VERSION "9"

NS_ :

BS_:

BU_: E115DCU

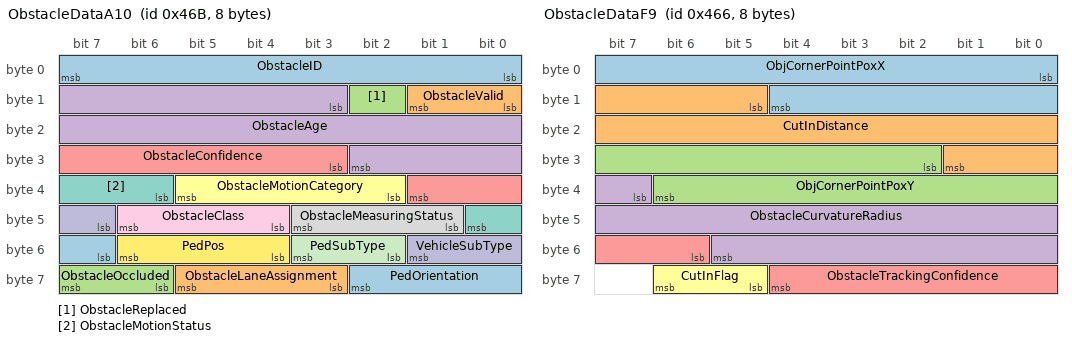
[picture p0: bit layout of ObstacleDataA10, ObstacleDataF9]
BO_ 1131 ObstacleDataA10: 8 E115DCU
 SG_ ObstacleID : 0|8@1+ (1,0) [0|255] "Counter"  E115DCU
 SG_ ObstacleValid : 8|2@1+ (1,0) [0|2] "Enum"  E115DCU
 SG_ ObstacleReplaced : 10|1@1+ (1,0) [0|1] "bool"  E115DCU
 SG_ ObstacleAge : 11|16@1+ (1,0) [0|65535] "Counter"  E115DCU
 SG_ ObstacleConfidence : 27|7@1+ (1,0) [0|100] "prob"  E115DCU
 SG_ ObstacleMotionCategory : 34|4@1+ (1,0) [0|13] "Enum"  E115DCU
 SG_ ObstacleMotionStatus : 38|3@1+ (1,0) [0|7] "Enum"  E115DCU
 SG_ ObstacleMeasuringStatus : 41|3@1+ (1,0) [0|7] "Enum"  E115DCU
 SG_ ObstacleClass : 44|3@1+ (1,0) [0|7] "Enum"  E115DCU
 SG_ VehicleSubType : 47|3@1+ (1,0) [0|7] "Enum"  E115DCU
 SG_ PedSubType : 50|2@1+ (1,0) [0|3] "Enum"  E115DCU
 SG_ PedPos : 52|3@1+ (1,0) [0|7] "Enum"  E115DCU
 SG_ PedOrientation : 55|4@1+ (1,0) [0|9] "Enum"  E115DCU
 SG_ ObstacleLaneAssignment : 59|3@1+ (1,0) [0|5] "Enum"  E115DCU
 SG_ ObstacleOccluded : 62|2@1+ (1,0) [0|3] "Enum"  E115DCU

BO_ 1126 ObstacleDataF9: 8 Vector__XXX
 SG_ ObjCornerPointPoxX : 0|13@1+ (0.0625,-250) [-250|250] "m" Vector__XXX
 SG_ CutInDistance : 13|13@1+ (0.01,-40.96) [-40.96|40.95] "m" Vector__XXX
 SG_ ObjCornerPointPoxY : 26|13@1+ (0.0625,-250) [-250|250] "m" Vector__XXX
 SG_ ObstacleCurvatureRadius : 39|15@1+ (1,-9999) [-9999|9999] "m" Vector__XXX
 SG_ ObstacleTrackingConfidence : 54|7@1+ (1,0) [0|100] "prob" Vector__XXX
 SG_ CutInFlag : 61|2@1+ (1,0) [0|2] "Enum" Vector__XXX

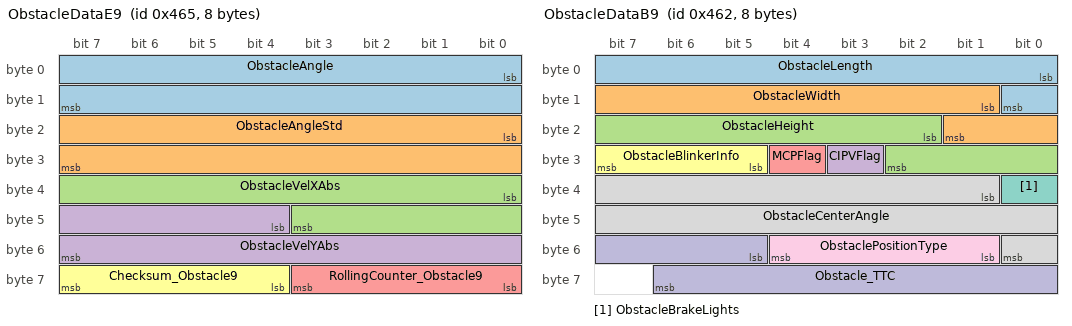
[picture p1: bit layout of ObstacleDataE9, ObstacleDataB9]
BO_ 1125 ObstacleDataE9: 8 E115DCU
 SG_ ObstacleAngle : 0|16@1+ (0.01,-327.68) [-327.68|327.67] "degree"  E115DCU
 SG_ ObstacleAngleStd : 16|16@1+ (0.01,0) [0|327.67] "degree"  E115DCU
 SG_ ObstacleVelXAbs : 32|12@1+ (0.05,-102.4) [-102.4|102.35] "m/sec"  E115DCU
 SG_ ObstacleVelYAbs : 44|12@1+ (0.05,-50) [-50|50] "m/sec"  E115DCU
 SG_ RollingCounter_Obstacle9 : 56|4@1+ (1,0) [0|15] "Counter"  E115DCU
 SG_ Checksum_Obstacle9 : 60|4@1+ (1,0) [0|15] "Counter"  E115DCU

BO_ 1124 ObstacleDataD9: 8 E115DCU
 SG_ ObstaclePosXSTD : 0|13@1+ (0.0625,0) [0|250] "m"  E115DCU
 SG_ ObstaclePosYSTD : 13|13@1+ (0.0625,0) [0|250] "m"  E115DCU
 SG_ ObstacleVelXSTD : 26|12@1+ (0.05,0) [0|102.35] "m/sec"  E115DCU
 SG_ ObstacleVelYSTD : 38|12@1+ (0.05,0) [0|50] "m/sec"  E115DCU
 SG_ ObstacleAccY : 50|10@1+ (0.03,-14.97) [-14.97|14.97] "m/s^2"  E115DCU

BO_ 1123 ObstacleDataC9: 8 E115DCU
 SG_ ObstaclePosX : 0|13@1+ (0.0625,-250) [-250|250] "m"  E115DCU
 SG_ ObstaclePosY : 13|13@1+ (0.0625,-250) [-250|250] "m"  E115DCU
 SG_ ObstacleVelX : 26|12@1+ (0.05,-102.4) [-102.4|102.35] "m/sec"  E115DCU
 SG_ ObstacleVelY : 38|12@1+ (0.05,-50) [-50|50] "m/sec"  E115DCU
 SG_ ObstacleAccX : 50|10@1+ (0.03,-14.97) [-14.97|14.97] "m/s^2"  E115DCU

BO_ 1122 ObstacleDataB9: 8 E115DCU
 SG_ ObstacleLength : 0|9@1+ (0.05,0) [0|25.6] "m"  E115DCU
 SG_ ObstacleWidth : 9|9@1+ (0.02,0) [0|10.24] "m"  E115DCU
 SG_ ObstacleHeight : 18|9@1+ (0.02,0) [0|10.24] "m"  E115DCU
 SG_ CIPVFlag : 27|1@1+ (1,0) [0|1] "bool"  E115DCU
 SG_ MCPFlag : 28|1@1+ (1,0) [0|1] "bool"  E115DCU
 SG_ ObstacleBlinkerInfo : 29|3@1+ (1,0) [0|4] "Enum"  E115DCU
 SG_ ObstacleBrakeLights : 32|1@1+ (1,0) [0|1] "bool"  E115DCU
 SG_ ObstacleCenterAngle : 33|16@1+ (0.01,-327.68) [-327.68|327.67] "degree"  E115DCU
 SG_ ObstaclePositionType : 49|4@1+ (1,0) [0|9] "Enum"  E115DCU
 SG_ Obstacle_TTC : 53|10@1+ (0.01,0) [0|10] "sec"  E115DCU

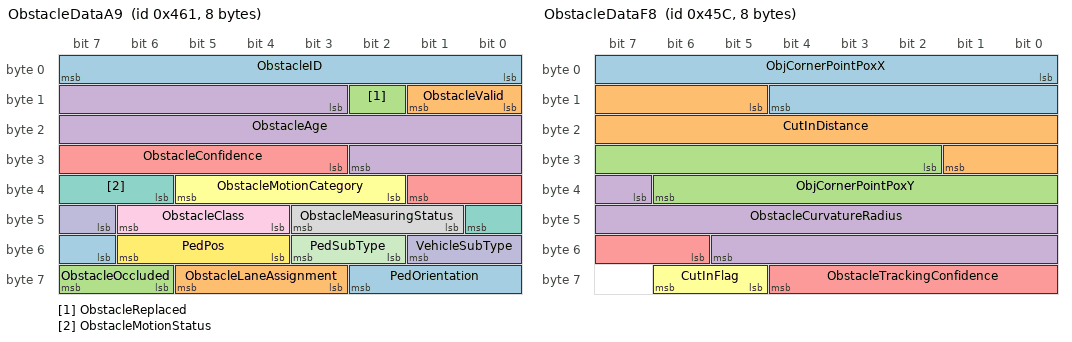
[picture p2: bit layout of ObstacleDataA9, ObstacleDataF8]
BO_ 1121 ObstacleDataA9: 8 E115DCU
 SG_ ObstacleID : 0|8@1+ (1,0) [0|255] "Counter"  E115DCU
 SG_ ObstacleValid : 8|2@1+ (1,0) [0|2] "Enum"  E115DCU
 SG_ ObstacleReplaced : 10|1@1+ (1,0) [0|1] "bool"  E115DCU
 SG_ ObstacleAge : 11|16@1+ (1,0) [0|65535] "Counter"  E115DCU
 SG_ ObstacleConfidence : 27|7@1+ (1,0) [0|100] "prob"  E115DCU
 SG_ ObstacleMotionCategory : 34|4@1+ (1,0) [0|13] "Enum"  E115DCU
 SG_ ObstacleMotionStatus : 38|3@1+ (1,0) [0|7] "Enum"  E115DCU
 SG_ ObstacleMeasuringStatus : 41|3@1+ (1,0) [0|7] "Enum"  E115DCU
 SG_ ObstacleClass : 44|3@1+ (1,0) [0|7] "Enum"  E115DCU
 SG_ VehicleSubType : 47|3@1+ (1,0) [0|7] "Enum"  E115DCU
 SG_ PedSubType : 50|2@1+ (1,0) [0|3] "Enum"  E115DCU
 SG_ PedPos : 52|3@1+ (1,0) [0|7] "Enum"  E115DCU
 SG_ PedOrientation : 55|4@1+ (1,0) [0|9] "Enum"  E115DCU
 SG_ ObstacleLaneAssignment : 59|3@1+ (1,0) [0|5] "Enum"  E115DCU
 SG_ ObstacleOccluded : 62|2@1+ (1,0) [0|3] "Enum"  E115DCU

BO_ 1116 ObstacleDataF8: 8 Vector__XXX
 SG_ ObjCornerPointPoxX : 0|13@1+ (0.0625,-250) [-250|250] "m" Vector__XXX
 SG_ CutInDistance : 13|13@1+ (0.01,-40.96) [-40.96|40.95] "m" Vector__XXX
 SG_ ObjCornerPointPoxY : 26|13@1+ (0.0625,-250) [-250|250] "m" Vector__XXX
 SG_ ObstacleCurvatureRadius : 39|15@1+ (1,-9999) [-9999|9999] "m" Vector__XXX
 SG_ ObstacleTrackingConfidence : 54|7@1+ (1,0) [0|100] "prob" Vector__XXX
 SG_ CutInFlag : 61|2@1+ (1,0) [0|2] "Enum" Vector__XXX

BO_ 1115 ObstacleDataE8: 8 E115DCU
 SG_ ObstacleAngle : 0|16@1+ (0.01,-327.68) [-327.68|327.67] "degree"  E115DCU
 SG_ ObstacleAngleStd : 16|16@1+ (0.01,0) [0|327.67] "degree"  E115DCU
 SG_ ObstacleVelXAbs : 32|12@1+ (0.05,-102.4) [-102.4|102.35] "m/sec"  E115DCU
 SG_ ObstacleVelYAbs : 44|12@1+ (0.05,-50) [-50|50] "m/sec"  E115DCU
 SG_ RollingCounter_Obstacle8 : 56|4@1+ (1,0) [0|15] "Counter"  E115DCU
 SG_ Checksum_Obstacle8 : 60|4@1+ (1,0) [0|15] "Counter"  E115DCU

BO_ 1114 ObstacleDataD8: 8 E115DCU
 SG_ ObstaclePosXSTD : 0|13@1+ (0.0625,0) [0|250] "m"  E115DCU
 SG_ ObstaclePosYSTD : 13|13@1+ (0.0625,0) [0|250] "m"  E115DCU
 SG_ ObstacleVelXSTD : 26|12@1+ (0.05,0) [0|102.35] "m/sec"  E115DCU
 SG_ ObstacleVelYSTD : 38|12@1+ (0.05,0) [0|50] "m/sec"  E115DCU
 SG_ ObstacleAccY : 50|10@1+ (0.03,-14.97) [-14.97|14.97] "m/s^2"  E115DCU

BO_ 1113 ObstacleDataC8: 8 E115DCU
 SG_ ObstaclePosX : 0|13@1+ (0.0625,-250) [-250|250] "m"  E115DCU
 SG_ ObstaclePosY : 13|13@1+ (0.0625,-250) [-250|250] "m"  E115DCU
 SG_ ObstacleVelX : 26|12@1+ (0.05,-102.4) [-102.4|102.35] "m/sec"  E115DCU
 SG_ ObstacleVelY : 38|12@1+ (0.05,-50) [-50|50] "m/sec"  E115DCU
 SG_ ObstacleAccX : 50|10@1+ (0.03,-14.97) [-14.97|14.97] "m/s^2"  E115DCU

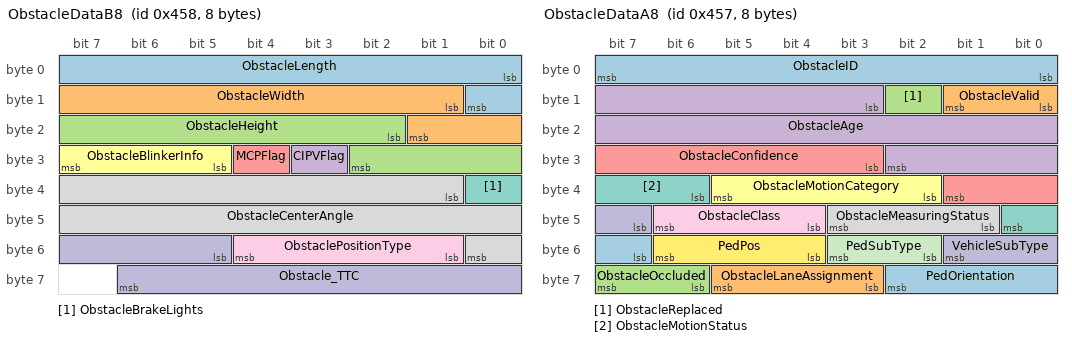
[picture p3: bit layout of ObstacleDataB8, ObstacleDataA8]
BO_ 1112 ObstacleDataB8: 8 E115DCU
 SG_ ObstacleLength : 0|9@1+ (0.05,0) [0|25.6] "m"  E115DCU
 SG_ ObstacleWidth : 9|9@1+ (0.02,0) [0|10.24] "m"  E115DCU
 SG_ ObstacleHeight : 18|9@1+ (0.02,0) [0|10.24] "m"  E115DCU
 SG_ CIPVFlag : 27|1@1+ (1,0) [0|1] "bool"  E115DCU
 SG_ MCPFlag : 28|1@1+ (1,0) [0|1] "bool"  E115DCU
 SG_ ObstacleBlinkerInfo : 29|3@1+ (1,0) [0|4] "Enum"  E115DCU
 SG_ ObstacleBrakeLights : 32|1@1+ (1,0) [0|1] "bool"  E115DCU
 SG_ ObstacleCenterAngle : 33|16@1+ (0.01,-327.68) [-327.68|327.67] "degree"  E115DCU
 SG_ ObstaclePositionType : 49|4@1+ (1,0) [0|9] "Enum"  E115DCU
 SG_ Obstacle_TTC : 53|10@1+ (0.01,0) [0|10] "sec"  E115DCU

BO_ 1111 ObstacleDataA8: 8 E115DCU
 SG_ ObstacleID : 0|8@1+ (1,0) [0|255] "Counter"  E115DCU
 SG_ ObstacleValid : 8|2@1+ (1,0) [0|2] "Enum"  E115DCU
 SG_ ObstacleReplaced : 10|1@1+ (1,0) [0|1] "bool"  E115DCU
 SG_ ObstacleAge : 11|16@1+ (1,0) [0|65535] "Counter"  E115DCU
 SG_ ObstacleConfidence : 27|7@1+ (1,0) [0|100] "prob"  E115DCU
 SG_ ObstacleMotionCategory : 34|4@1+ (1,0) [0|13] "Enum"  E115DCU
 SG_ ObstacleMotionStatus : 38|3@1+ (1,0) [0|7] "Enum"  E115DCU
 SG_ ObstacleMeasuringStatus : 41|3@1+ (1,0) [0|7] "Enum"  E115DCU
 SG_ ObstacleClass : 44|3@1+ (1,0) [0|7] "Enum"  E115DCU
 SG_ VehicleSubType : 47|3@1+ (1,0) [0|7] "Enum"  E115DCU
 SG_ PedSubType : 50|2@1+ (1,0) [0|3] "Enum"  E115DCU
 SG_ PedPos : 52|3@1+ (1,0) [0|7] "Enum"  E115DCU
 SG_ PedOrientation : 55|4@1+ (1,0) [0|9] "Enum"  E115DCU
 SG_ ObstacleLaneAssignment : 59|3@1+ (1,0) [0|5] "Enum"  E115DCU
 SG_ ObstacleOccluded : 62|2@1+ (1,0) [0|3] "Enum"  E115DCU

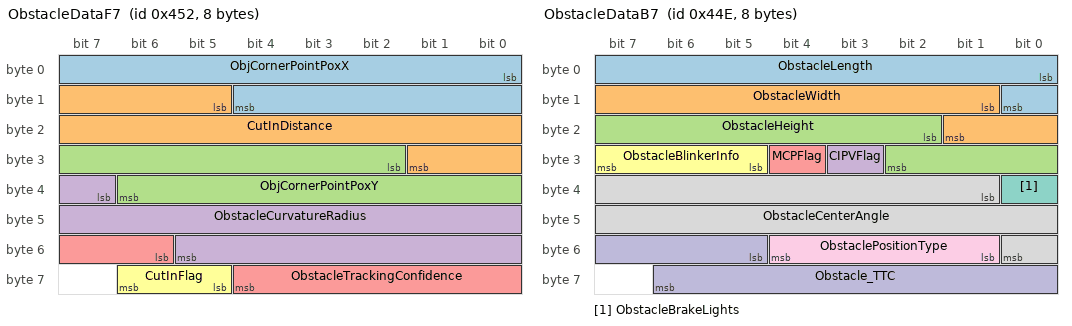
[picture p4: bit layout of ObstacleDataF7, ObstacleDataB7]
BO_ 1106 ObstacleDataF7: 8 Vector__XXX
 SG_ ObjCornerPointPoxX : 0|13@1+ (0.0625,-250) [-250|250] "m" Vector__XXX
 SG_ CutInDistance : 13|13@1+ (0.01,-40.96) [-40.96|40.95] "m" Vector__XXX
 SG_ ObjCornerPointPoxY : 26|13@1+ (0.0625,-250) [-250|250] "m" Vector__XXX
 SG_ ObstacleCurvatureRadius : 39|15@1+ (1,-9999) [-9999|9999] "m" Vector__XXX
 SG_ ObstacleTrackingConfidence : 54|7@1+ (1,0) [0|100] "prob" Vector__XXX
 SG_ CutInFlag : 61|2@1+ (1,0) [0|2] "Enum" Vector__XXX

BO_ 1105 ObstacleDataE7: 8 E115DCU
 SG_ ObstacleAngle : 0|16@1+ (0.01,-327.68) [-327.68|327.67] "degree"  E115DCU
 SG_ ObstacleAngleStd : 16|16@1+ (0.01,0) [0|327.67] "degree"  E115DCU
 SG_ ObstacleVelXAbs : 32|12@1+ (0.05,-102.4) [-102.4|102.35] "m/sec"  E115DCU
 SG_ ObstacleVelYAbs : 44|12@1+ (0.05,-50) [-50|50] "m/sec"  E115DCU
 SG_ RollingCounter_Obstacle7 : 56|4@1+ (1,0) [0|15] "Counter"  E115DCU
 SG_ Checksum_Obstacle7 : 60|4@1+ (1,0) [0|15] "Counter"  E115DCU

BO_ 1104 ObstacleDataD7: 8 E115DCU
 SG_ ObstaclePosXSTD : 0|13@1+ (0.0625,0) [0|250] "m"  E115DCU
 SG_ ObstaclePosYSTD : 13|13@1+ (0.0625,0) [0|250] "m"  E115DCU
 SG_ ObstacleVelXSTD : 26|12@1+ (0.05,0) [0|102.35] "m/sec"  E115DCU
 SG_ ObstacleVelYSTD : 38|12@1+ (0.05,0) [0|50] "m/sec"  E115DCU
 SG_ ObstacleAccY : 50|10@1+ (0.03,-14.97) [-14.97|14.97] "m/s^2"  E115DCU

BO_ 1103 ObstacleDataC7: 8 E115DCU
 SG_ ObstaclePosX : 0|13@1+ (0.0625,-250) [-250|250] "m"  E115DCU
 SG_ ObstaclePosY : 13|13@1+ (0.0625,-250) [-250|250] "m"  E115DCU
 SG_ ObstacleVelX : 26|12@1+ (0.05,-102.4) [-102.4|102.35] "m/sec"  E115DCU
 SG_ ObstacleVelY : 38|12@1+ (0.05,-50) [-50|50] "m/sec"  E115DCU
 SG_ ObstacleAccX : 50|10@1+ (0.03,-14.97) [-14.97|14.97] "m/s^2"  E115DCU

BO_ 1102 ObstacleDataB7: 8 E115DCU
 SG_ ObstacleLength : 0|9@1+ (0.05,0) [0|25.6] "m"  E115DCU
 SG_ ObstacleWidth : 9|9@1+ (0.02,0) [0|10.24] "m"  E115DCU
 SG_ ObstacleHeight : 18|9@1+ (0.02,0) [0|10.24] "m"  E115DCU
 SG_ CIPVFlag : 27|1@1+ (1,0) [0|1] "bool"  E115DCU
 SG_ MCPFlag : 28|1@1+ (1,0) [0|1] "bool"  E115DCU
 SG_ ObstacleBlinkerInfo : 29|3@1+ (1,0) [0|4] "Enum"  E115DCU
 SG_ ObstacleBrakeLights : 32|1@1+ (1,0) [0|1] "bool"  E115DCU
 SG_ ObstacleCenterAngle : 33|16@1+ (0.01,-327.68) [-327.68|327.67] "degree"  E115DCU
 SG_ ObstaclePositionType : 49|4@1+ (1,0) [0|9] "Enum"  E115DCU
 SG_ Obstacle_TTC : 53|10@1+ (0.01,0) [0|10] "sec"  E115DCU

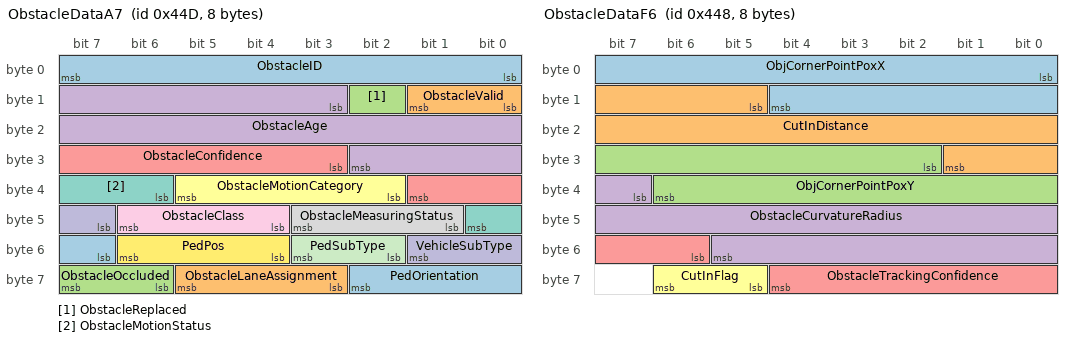
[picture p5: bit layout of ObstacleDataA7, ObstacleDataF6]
BO_ 1101 ObstacleDataA7: 8 E115DCU
 SG_ ObstacleID : 0|8@1+ (1,0) [0|255] "Counter"  E115DCU
 SG_ ObstacleValid : 8|2@1+ (1,0) [0|2] "Enum"  E115DCU
 SG_ ObstacleReplaced : 10|1@1+ (1,0) [0|1] "bool"  E115DCU
 SG_ ObstacleAge : 11|16@1+ (1,0) [0|65535] "Counter"  E115DCU
 SG_ ObstacleConfidence : 27|7@1+ (1,0) [0|100] "prob"  E115DCU
 SG_ ObstacleMotionCategory : 34|4@1+ (1,0) [0|13] "Enum"  E115DCU
 SG_ ObstacleMotionStatus : 38|3@1+ (1,0) [0|7] "Enum"  E115DCU
 SG_ ObstacleMeasuringStatus : 41|3@1+ (1,0) [0|7] "Enum"  E115DCU
 SG_ ObstacleClass : 44|3@1+ (1,0) [0|7] "Enum"  E115DCU
 SG_ VehicleSubType : 47|3@1+ (1,0) [0|7] "Enum"  E115DCU
 SG_ PedSubType : 50|2@1+ (1,0) [0|3] "Enum"  E115DCU
 SG_ PedPos : 52|3@1+ (1,0) [0|7] "Enum"  E115DCU
 SG_ PedOrientation : 55|4@1+ (1,0) [0|9] "Enum"  E115DCU
 SG_ ObstacleLaneAssignment : 59|3@1+ (1,0) [0|5] "Enum"  E115DCU
 SG_ ObstacleOccluded : 62|2@1+ (1,0) [0|3] "Enum"  E115DCU

BO_ 1096 ObstacleDataF6: 8 Vector__XXX
 SG_ ObjCornerPointPoxX : 0|13@1+ (0.0625,-250) [-250|250] "m" Vector__XXX
 SG_ CutInDistance : 13|13@1+ (0.01,-40.96) [-40.96|40.95] "m" Vector__XXX
 SG_ ObjCornerPointPoxY : 26|13@1+ (0.0625,-250) [-250|250] "m" Vector__XXX
 SG_ ObstacleCurvatureRadius : 39|15@1+ (1,-9999) [-9999|9999] "m" Vector__XXX
 SG_ ObstacleTrackingConfidence : 54|7@1+ (1,0) [0|100] "prob" Vector__XXX
 SG_ CutInFlag : 61|2@1+ (1,0) [0|2] "Enum" Vector__XXX

BO_ 1095 ObstacleDataE6: 8 E115DCU
 SG_ ObstacleAngle : 0|16@1+ (0.01,-327.68) [-327.68|327.67] "degree"  E115DCU
 SG_ ObstacleAngleStd : 16|16@1+ (0.01,0) [0|327.67] "degree"  E115DCU
 SG_ ObstacleVelXAbs : 32|12@1+ (0.05,-102.4) [-102.4|102.35] "m/sec"  E115DCU
 SG_ ObstacleVelYAbs : 44|12@1+ (0.05,-50) [-50|50] "m/sec"  E115DCU
 SG_ RollingCounter_Obstacle6 : 56|4@1+ (1,0) [0|15] "Counter"  E115DCU
 SG_ Checksum_Obstacle6 : 60|4@1+ (1,0) [0|15] "Counter"  E115DCU

BO_ 1094 ObstacleDataD6: 8 E115DCU
 SG_ ObstaclePosXSTD : 0|13@1+ (0.0625,0) [0|250] "m"  E115DCU
 SG_ ObstaclePosYSTD : 13|13@1+ (0.0625,0) [0|250] "m"  E115DCU
 SG_ ObstacleVelXSTD : 26|12@1+ (0.05,0) [0|102.35] "m/sec"  E115DCU
 SG_ ObstacleVelYSTD : 38|12@1+ (0.05,0) [0|50] "m/sec"  E115DCU
 SG_ ObstacleAccY : 50|10@1+ (0.03,-14.97) [-14.97|14.97] "m/s^2"  E115DCU

BO_ 1093 ObstacleDataC6: 8 E115DCU
 SG_ ObstaclePosX : 0|13@1+ (0.0625,-250) [-250|250] "m"  E115DCU
 SG_ ObstaclePosY : 13|13@1+ (0.0625,-250) [-250|250] "m"  E115DCU
 SG_ ObstacleVelX : 26|12@1+ (0.05,-102.4) [-102.4|102.35] "m/sec"  E115DCU
 SG_ ObstacleVelY : 38|12@1+ (0.05,-50) [-50|50] "m/sec"  E115DCU
 SG_ ObstacleAccX : 50|10@1+ (0.03,-14.97) [-14.97|14.97] "m/s^2"  E115DCU

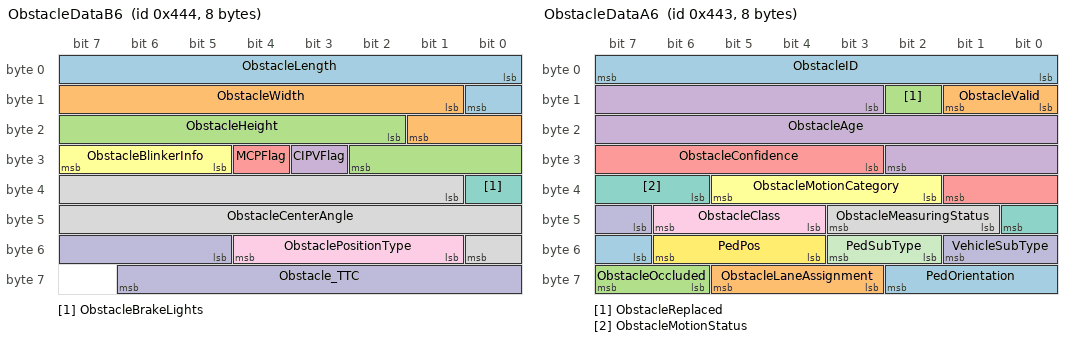
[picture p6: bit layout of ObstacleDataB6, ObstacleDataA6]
BO_ 1092 ObstacleDataB6: 8 E115DCU
 SG_ ObstacleLength : 0|9@1+ (0.05,0) [0|25.6] "m"  E115DCU
 SG_ ObstacleWidth : 9|9@1+ (0.02,0) [0|10.24] "m"  E115DCU
 SG_ ObstacleHeight : 18|9@1+ (0.02,0) [0|10.24] "m"  E115DCU
 SG_ CIPVFlag : 27|1@1+ (1,0) [0|1] "bool"  E115DCU
 SG_ MCPFlag : 28|1@1+ (1,0) [0|1] "bool"  E115DCU
 SG_ ObstacleBlinkerInfo : 29|3@1+ (1,0) [0|4] "Enum"  E115DCU
 SG_ ObstacleBrakeLights : 32|1@1+ (1,0) [0|1] "bool"  E115DCU
 SG_ ObstacleCenterAngle : 33|16@1+ (0.01,-327.68) [-327.68|327.67] "degree"  E115DCU
 SG_ ObstaclePositionType : 49|4@1+ (1,0) [0|9] "Enum"  E115DCU
 SG_ Obstacle_TTC : 53|10@1+ (0.01,0) [0|10] "sec"  E115DCU

BO_ 1091 ObstacleDataA6: 8 E115DCU
 SG_ ObstacleID : 0|8@1+ (1,0) [0|255] "Counter"  E115DCU
 SG_ ObstacleValid : 8|2@1+ (1,0) [0|2] "Enum"  E115DCU
 SG_ ObstacleReplaced : 10|1@1+ (1,0) [0|1] "bool"  E115DCU
 SG_ ObstacleAge : 11|16@1+ (1,0) [0|65535] "Counter"  E115DCU
 SG_ ObstacleConfidence : 27|7@1+ (1,0) [0|100] "prob"  E115DCU
 SG_ ObstacleMotionCategory : 34|4@1+ (1,0) [0|13] "Enum"  E115DCU
 SG_ ObstacleMotionStatus : 38|3@1+ (1,0) [0|7] "Enum"  E115DCU
 SG_ ObstacleMeasuringStatus : 41|3@1+ (1,0) [0|7] "Enum"  E115DCU
 SG_ ObstacleClass : 44|3@1+ (1,0) [0|7] "Enum"  E115DCU
 SG_ VehicleSubType : 47|3@1+ (1,0) [0|7] "Enum"  E115DCU
 SG_ PedSubType : 50|2@1+ (1,0) [0|3] "Enum"  E115DCU
 SG_ PedPos : 52|3@1+ (1,0) [0|7] "Enum"  E115DCU
 SG_ PedOrientation : 55|4@1+ (1,0) [0|9] "Enum"  E115DCU
 SG_ ObstacleLaneAssignment : 59|3@1+ (1,0) [0|5] "Enum"  E115DCU
 SG_ ObstacleOccluded : 62|2@1+ (1,0) [0|3] "Enum"  E115DCU

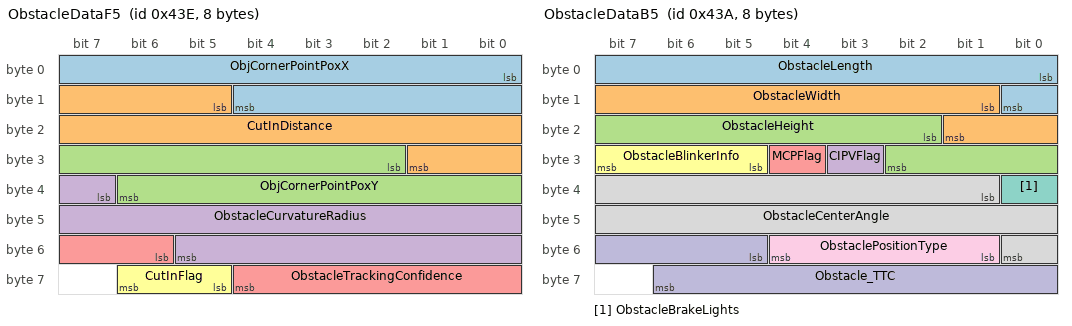
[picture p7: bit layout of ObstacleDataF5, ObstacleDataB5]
BO_ 1086 ObstacleDataF5: 8 Vector__XXX
 SG_ ObjCornerPointPoxX : 0|13@1+ (0.0625,-250) [-250|250] "m" Vector__XXX
 SG_ CutInDistance : 13|13@1+ (0.01,-40.96) [-40.96|40.95] "m" Vector__XXX
 SG_ ObjCornerPointPoxY : 26|13@1+ (0.0625,-250) [-250|250] "m" Vector__XXX
 SG_ ObstacleCurvatureRadius : 39|15@1+ (1,-9999) [-9999|9999] "m" Vector__XXX
 SG_ ObstacleTrackingConfidence : 54|7@1+ (1,0) [0|100] "prob" Vector__XXX
 SG_ CutInFlag : 61|2@1+ (1,0) [0|2] "Enum" Vector__XXX

BO_ 1085 ObstacleDataE5: 8 E115DCU
 SG_ ObstacleAngle : 0|16@1+ (0.01,-327.68) [-327.68|327.67] "degree"  E115DCU
 SG_ ObstacleAngleStd : 16|16@1+ (0.01,0) [0|327.67] "degree"  E115DCU
 SG_ ObstacleVelXAbs : 32|12@1+ (0.05,-102.4) [-102.4|102.35] "m/sec"  E115DCU
 SG_ ObstacleVelYAbs : 44|12@1+ (0.05,-50) [-50|50] "m/sec"  E115DCU
 SG_ RollingCounter_Obstacle5 : 56|4@1+ (1,0) [0|15] "Counter"  E115DCU
 SG_ Checksum_Obstacle5 : 60|4@1+ (1,0) [0|15] "Counter"  E115DCU

BO_ 1084 ObstacleDataD5: 8 E115DCU
 SG_ ObstaclePosXSTD : 0|13@1+ (0.0625,0) [0|250] "m"  E115DCU
 SG_ ObstaclePosYSTD : 13|13@1+ (0.0625,0) [0|250] "m"  E115DCU
 SG_ ObstacleVelXSTD : 26|12@1+ (0.05,0) [0|102.35] "m/sec"  E115DCU
 SG_ ObstacleVelYSTD : 38|12@1+ (0.05,0) [0|50] "m/sec"  E115DCU
 SG_ ObstacleAccY : 50|10@1+ (0.03,-14.97) [-14.97|14.97] "m/s^2"  E115DCU

BO_ 1083 ObstacleDataC5: 8 E115DCU
 SG_ ObstaclePosX : 0|13@1+ (0.0625,-250) [-250|250] "m"  E115DCU
 SG_ ObstaclePosY : 13|13@1+ (0.0625,-250) [-250|250] "m"  E115DCU
 SG_ ObstacleVelX : 26|12@1+ (0.05,-102.4) [-102.4|102.35] "m/sec"  E115DCU
 SG_ ObstacleVelY : 38|12@1+ (0.05,-50) [-50|50] "m/sec"  E115DCU
 SG_ ObstacleAccX : 50|10@1+ (0.03,-14.97) [-14.97|14.97] "m/s^2"  E115DCU

BO_ 1082 ObstacleDataB5: 8 E115DCU
 SG_ ObstacleLength : 0|9@1+ (0.05,0) [0|25.6] "m"  E115DCU
 SG_ ObstacleWidth : 9|9@1+ (0.02,0) [0|10.24] "m"  E115DCU
 SG_ ObstacleHeight : 18|9@1+ (0.02,0) [0|10.24] "m"  E115DCU
 SG_ CIPVFlag : 27|1@1+ (1,0) [0|1] "bool"  E115DCU
 SG_ MCPFlag : 28|1@1+ (1,0) [0|1] "bool"  E115DCU
 SG_ ObstacleBlinkerInfo : 29|3@1+ (1,0) [0|4] "Enum"  E115DCU
 SG_ ObstacleBrakeLights : 32|1@1+ (1,0) [0|1] "bool"  E115DCU
 SG_ ObstacleCenterAngle : 33|16@1+ (0.01,-327.68) [-327.68|327.67] "degree"  E115DCU
 SG_ ObstaclePositionType : 49|4@1+ (1,0) [0|9] "Enum"  E115DCU
 SG_ Obstacle_TTC : 53|10@1+ (0.01,0) [0|10] "sec"  E115DCU

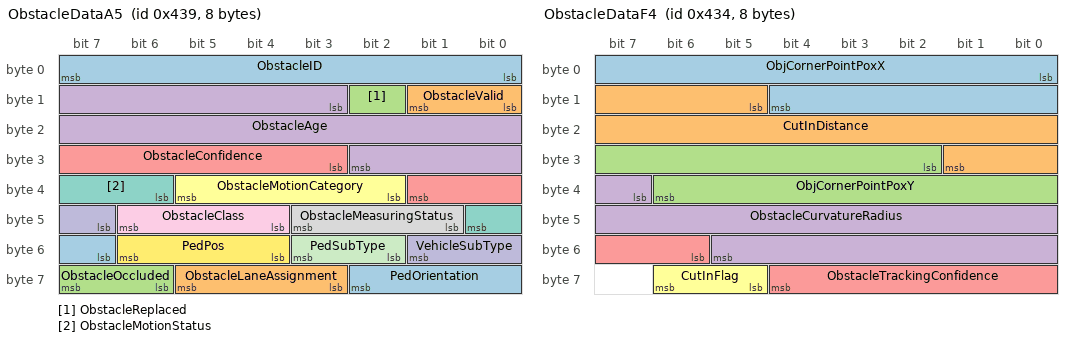
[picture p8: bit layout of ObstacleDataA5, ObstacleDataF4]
BO_ 1081 ObstacleDataA5: 8 E115DCU
 SG_ ObstacleID : 0|8@1+ (1,0) [0|255] "Counter"  E115DCU
 SG_ ObstacleValid : 8|2@1+ (1,0) [0|2] "Enum"  E115DCU
 SG_ ObstacleReplaced : 10|1@1+ (1,0) [0|1] "bool"  E115DCU
 SG_ ObstacleAge : 11|16@1+ (1,0) [0|65535] "Counter"  E115DCU
 SG_ ObstacleConfidence : 27|7@1+ (1,0) [0|100] "prob"  E115DCU
 SG_ ObstacleMotionCategory : 34|4@1+ (1,0) [0|13] "Enum"  E115DCU
 SG_ ObstacleMotionStatus : 38|3@1+ (1,0) [0|7] "Enum"  E115DCU
 SG_ ObstacleMeasuringStatus : 41|3@1+ (1,0) [0|7] "Enum"  E115DCU
 SG_ ObstacleClass : 44|3@1+ (1,0) [0|7] "Enum"  E115DCU
 SG_ VehicleSubType : 47|3@1+ (1,0) [0|7] "Enum"  E115DCU
 SG_ PedSubType : 50|2@1+ (1,0) [0|3] "Enum"  E115DCU
 SG_ PedPos : 52|3@1+ (1,0) [0|7] "Enum"  E115DCU
 SG_ PedOrientation : 55|4@1+ (1,0) [0|9] "Enum"  E115DCU
 SG_ ObstacleLaneAssignment : 59|3@1+ (1,0) [0|5] "Enum"  E115DCU
 SG_ ObstacleOccluded : 62|2@1+ (1,0) [0|3] "Enum"  E115DCU

BO_ 1076 ObstacleDataF4: 8 Vector__XXX
 SG_ ObjCornerPointPoxX : 0|13@1+ (0.0625,-250) [-250|250] "m" Vector__XXX
 SG_ CutInDistance : 13|13@1+ (0.01,-40.96) [-40.96|40.95] "m" Vector__XXX
 SG_ ObjCornerPointPoxY : 26|13@1+ (0.0625,-250) [-250|250] "m" Vector__XXX
 SG_ ObstacleCurvatureRadius : 39|15@1+ (1,-9999) [-9999|9999] "m" Vector__XXX
 SG_ ObstacleTrackingConfidence : 54|7@1+ (1,0) [0|100] "prob" Vector__XXX
 SG_ CutInFlag : 61|2@1+ (1,0) [0|2] "Enum" Vector__XXX

BO_ 1075 ObstacleDataE4: 8 E115DCU
 SG_ ObstacleAngle : 0|16@1+ (0.01,-327.68) [-327.68|327.67] "degree"  E115DCU
 SG_ ObstacleAngleStd : 16|16@1+ (0.01,0) [0|327.67] "degree"  E115DCU
 SG_ ObstacleVelXAbs : 32|12@1+ (0.05,-102.4) [-102.4|102.35] "m/sec"  E115DCU
 SG_ ObstacleVelYAbs : 44|12@1+ (0.05,-50) [-50|50] "m/sec"  E115DCU
 SG_ RollingCounter_Obstacle4 : 56|4@1+ (1,0) [0|15] "Counter"  E115DCU
 SG_ Checksum_Obstacle4 : 60|4@1+ (1,0) [0|15] "Counter"  E115DCU

BO_ 1074 ObstacleDataD4: 8 E115DCU
 SG_ ObstaclePosXSTD : 0|13@1+ (0.0625,0) [0|250] "m"  E115DCU
 SG_ ObstaclePosYSTD : 13|13@1+ (0.0625,0) [0|250] "m"  E115DCU
 SG_ ObstacleVelXSTD : 26|12@1+ (0.05,0) [0|102.35] "m/sec"  E115DCU
 SG_ ObstacleVelYSTD : 38|12@1+ (0.05,0) [0|50] "m/sec"  E115DCU
 SG_ ObstacleAccY : 50|10@1+ (0.03,-14.97) [-14.97|14.97] "m/s^2"  E115DCU

BO_ 1073 ObstacleDataC4: 8 E115DCU
 SG_ ObstaclePosX : 0|13@1+ (0.0625,-250) [-250|250] "m"  E115DCU
 SG_ ObstaclePosY : 13|13@1+ (0.0625,-250) [-250|250] "m"  E115DCU
 SG_ ObstacleVelX : 26|12@1+ (0.05,-102.4) [-102.4|102.35] "m/sec"  E115DCU
 SG_ ObstacleVelY : 38|12@1+ (0.05,-50) [-50|50] "m/sec"  E115DCU
 SG_ ObstacleAccX : 50|10@1+ (0.03,-14.97) [-14.97|14.97] "m/s^2"  E115DCU

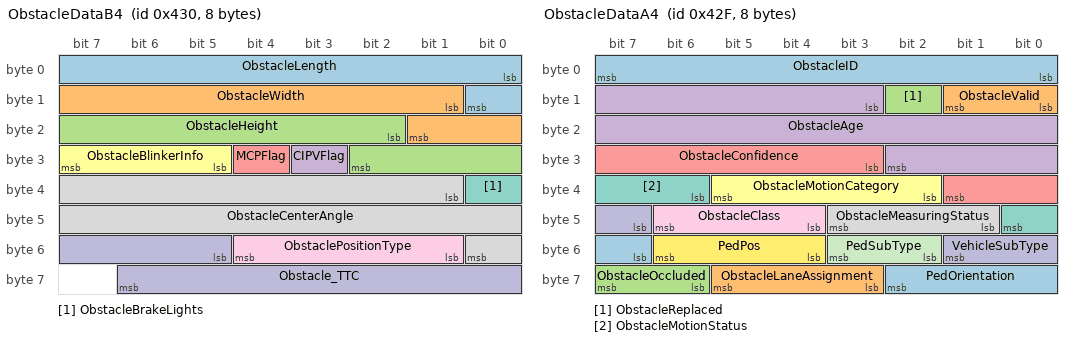
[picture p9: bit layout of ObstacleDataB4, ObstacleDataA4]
BO_ 1072 ObstacleDataB4: 8 E115DCU
 SG_ ObstacleLength : 0|9@1+ (0.05,0) [0|25.6] "m"  E115DCU
 SG_ ObstacleWidth : 9|9@1+ (0.02,0) [0|10.24] "m"  E115DCU
 SG_ ObstacleHeight : 18|9@1+ (0.02,0) [0|10.24] "m"  E115DCU
 SG_ CIPVFlag : 27|1@1+ (1,0) [0|1] "bool"  E115DCU
 SG_ MCPFlag : 28|1@1+ (1,0) [0|1] "bool"  E115DCU
 SG_ ObstacleBlinkerInfo : 29|3@1+ (1,0) [0|4] "Enum"  E115DCU
 SG_ ObstacleBrakeLights : 32|1@1+ (1,0) [0|1] "bool"  E115DCU
 SG_ ObstacleCenterAngle : 33|16@1+ (0.01,-327.68) [-327.68|327.67] "degree"  E115DCU
 SG_ ObstaclePositionType : 49|4@1+ (1,0) [0|9] "Enum"  E115DCU
 SG_ Obstacle_TTC : 53|10@1+ (0.01,0) [0|10] "sec"  E115DCU

BO_ 1071 ObstacleDataA4: 8 E115DCU
 SG_ ObstacleID : 0|8@1+ (1,0) [0|255] "Counter"  E115DCU
 SG_ ObstacleValid : 8|2@1+ (1,0) [0|2] "Enum"  E115DCU
 SG_ ObstacleReplaced : 10|1@1+ (1,0) [0|1] "bool"  E115DCU
 SG_ ObstacleAge : 11|16@1+ (1,0) [0|65535] "Counter"  E115DCU
 SG_ ObstacleConfidence : 27|7@1+ (1,0) [0|100] "prob"  E115DCU
 SG_ ObstacleMotionCategory : 34|4@1+ (1,0) [0|13] "Enum"  E115DCU
 SG_ ObstacleMotionStatus : 38|3@1+ (1,0) [0|7] "Enum"  E115DCU
 SG_ ObstacleMeasuringStatus : 41|3@1+ (1,0) [0|7] "Enum"  E115DCU
 SG_ ObstacleClass : 44|3@1+ (1,0) [0|7] "Enum"  E115DCU
 SG_ VehicleSubType : 47|3@1+ (1,0) [0|7] "Enum"  E115DCU
 SG_ PedSubType : 50|2@1+ (1,0) [0|3] "Enum"  E115DCU
 SG_ PedPos : 52|3@1+ (1,0) [0|7] "Enum"  E115DCU
 SG_ PedOrientation : 55|4@1+ (1,0) [0|9] "Enum"  E115DCU
 SG_ ObstacleLaneAssignment : 59|3@1+ (1,0) [0|5] "Enum"  E115DCU
 SG_ ObstacleOccluded : 62|2@1+ (1,0) [0|3] "Enum"  E115DCU

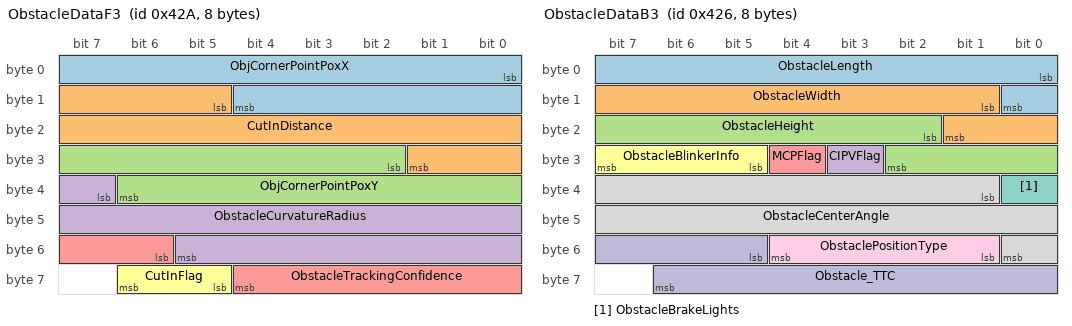
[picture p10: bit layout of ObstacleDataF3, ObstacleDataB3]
BO_ 1066 ObstacleDataF3: 8 Vector__XXX
 SG_ ObjCornerPointPoxX : 0|13@1+ (0.0625,-250) [-250|250] "m" Vector__XXX
 SG_ CutInDistance : 13|13@1+ (0.01,-40.96) [-40.96|40.95] "m" Vector__XXX
 SG_ ObjCornerPointPoxY : 26|13@1+ (0.0625,-250) [-250|250] "m" Vector__XXX
 SG_ ObstacleCurvatureRadius : 39|15@1+ (1,-9999) [-9999|9999] "m" Vector__XXX
 SG_ ObstacleTrackingConfidence : 54|7@1+ (1,0) [0|100] "prob" Vector__XXX
 SG_ CutInFlag : 61|2@1+ (1,0) [0|2] "Enum" Vector__XXX

BO_ 1065 ObstacleDataE3: 8 E115DCU
 SG_ ObstacleAngle : 0|16@1+ (0.01,-327.68) [-327.68|327.67] "degree"  E115DCU
 SG_ ObstacleAngleStd : 16|16@1+ (0.01,0) [0|327.67] "degree"  E115DCU
 SG_ ObstacleVelXAbs : 32|12@1+ (0.05,-102.4) [-102.4|102.35] "m/sec"  E115DCU
 SG_ ObstacleVelYAbs : 44|12@1+ (0.05,-50) [-50|50] "m/sec"  E115DCU
 SG_ RollingCounter_Obstacle3 : 56|4@1+ (1,0) [0|15] "Counter"  E115DCU
 SG_ Checksum_Obstacle3 : 60|4@1+ (1,0) [0|15] "Counter"  E115DCU

BO_ 1064 ObstacleDataD3: 8 E115DCU
 SG_ ObstaclePosXSTD : 0|13@1+ (0.0625,0) [0|250] "m"  E115DCU
 SG_ ObstaclePosYSTD : 13|13@1+ (0.0625,0) [0|250] "m"  E115DCU
 SG_ ObstacleVelXSTD : 26|12@1+ (0.05,0) [0|102.35] "m/sec"  E115DCU
 SG_ ObstacleVelYSTD : 38|12@1+ (0.05,0) [0|50] "m/sec"  E115DCU
 SG_ ObstacleAccY : 50|10@1+ (0.03,-14.97) [-14.97|14.97] "m/s^2"  E115DCU

BO_ 1063 ObstacleDataC3: 8 E115DCU
 SG_ ObstaclePosX : 0|13@1+ (0.0625,-250) [-250|250] "m"  E115DCU
 SG_ ObstaclePosY : 13|13@1+ (0.0625,-250) [-250|250] "m"  E115DCU
 SG_ ObstacleVelX : 26|12@1+ (0.05,-102.4) [-102.4|102.35] "m/sec"  E115DCU
 SG_ ObstacleVelY : 38|12@1+ (0.05,-50) [-50|50] "m/sec"  E115DCU
 SG_ ObstacleAccX : 50|10@1+ (0.03,-14.97) [-14.97|14.97] "m/s^2"  E115DCU

BO_ 1062 ObstacleDataB3: 8 E115DCU
 SG_ ObstacleLength : 0|9@1+ (0.05,0) [0|25.6] "m"  E115DCU
 SG_ ObstacleWidth : 9|9@1+ (0.02,0) [0|10.24] "m"  E115DCU
 SG_ ObstacleHeight : 18|9@1+ (0.02,0) [0|10.24] "m"  E115DCU
 SG_ CIPVFlag : 27|1@1+ (1,0) [0|1] "bool"  E115DCU
 SG_ MCPFlag : 28|1@1+ (1,0) [0|1] "bool"  E115DCU
 SG_ ObstacleBlinkerInfo : 29|3@1+ (1,0) [0|4] "Enum"  E115DCU
 SG_ ObstacleBrakeLights : 32|1@1+ (1,0) [0|1] "bool"  E115DCU
 SG_ ObstacleCenterAngle : 33|16@1+ (0.01,-327.68) [-327.68|327.67] "degree"  E115DCU
 SG_ ObstaclePositionType : 49|4@1+ (1,0) [0|9] "Enum"  E115DCU
 SG_ Obstacle_TTC : 53|10@1+ (0.01,0) [0|10] "sec"  E115DCU

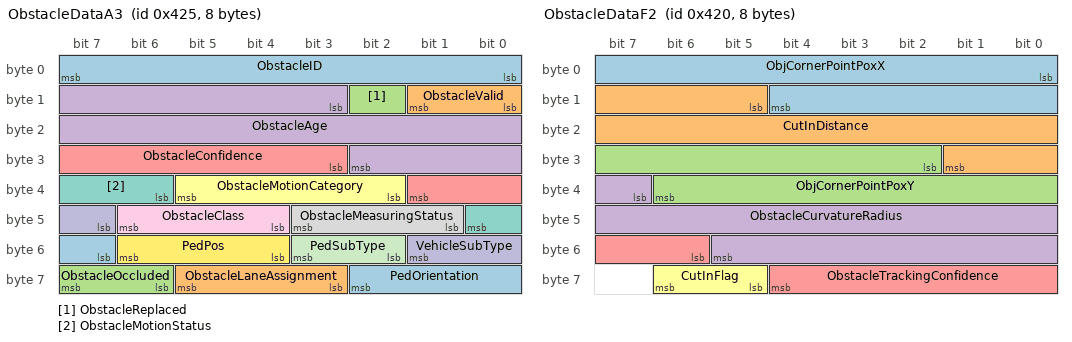
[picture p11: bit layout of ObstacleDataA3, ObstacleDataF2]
BO_ 1061 ObstacleDataA3: 8 E115DCU
 SG_ ObstacleID : 0|8@1+ (1,0) [0|255] "Counter"  E115DCU
 SG_ ObstacleValid : 8|2@1+ (1,0) [0|2] "Enum"  E115DCU
 SG_ ObstacleReplaced : 10|1@1+ (1,0) [0|1] "bool"  E115DCU
 SG_ ObstacleAge : 11|16@1+ (1,0) [0|65535] "Counter"  E115DCU
 SG_ ObstacleConfidence : 27|7@1+ (1,0) [0|100] "prob"  E115DCU
 SG_ ObstacleMotionCategory : 34|4@1+ (1,0) [0|13] "Enum"  E115DCU
 SG_ ObstacleMotionStatus : 38|3@1+ (1,0) [0|7] "Enum"  E115DCU
 SG_ ObstacleMeasuringStatus : 41|3@1+ (1,0) [0|7] "Enum"  E115DCU
 SG_ ObstacleClass : 44|3@1+ (1,0) [0|7] "Enum"  E115DCU
 SG_ VehicleSubType : 47|3@1+ (1,0) [0|7] "Enum"  E115DCU
 SG_ PedSubType : 50|2@1+ (1,0) [0|3] "Enum"  E115DCU
 SG_ PedPos : 52|3@1+ (1,0) [0|7] "Enum"  E115DCU
 SG_ PedOrientation : 55|4@1+ (1,0) [0|9] "Enum"  E115DCU
 SG_ ObstacleLaneAssignment : 59|3@1+ (1,0) [0|5] "Enum"  E115DCU
 SG_ ObstacleOccluded : 62|2@1+ (1,0) [0|3] "Enum"  E115DCU

BO_ 1056 ObstacleDataF2: 8 Vector__XXX
 SG_ ObjCornerPointPoxX : 0|13@1+ (0.0625,-250) [-250|250] "m" Vector__XXX
 SG_ CutInDistance : 13|13@1+ (0.01,-40.96) [-40.96|40.95] "m" Vector__XXX
 SG_ ObjCornerPointPoxY : 26|13@1+ (0.0625,-250) [-250|250] "m" Vector__XXX
 SG_ ObstacleCurvatureRadius : 39|15@1+ (1,-9999) [-9999|9999] "m" Vector__XXX
 SG_ ObstacleTrackingConfidence : 54|7@1+ (1,0) [0|100] "prob" Vector__XXX
 SG_ CutInFlag : 61|2@1+ (1,0) [0|2] "Enum" Vector__XXX

BO_ 1055 ObstacleDataE2: 8 E115DCU
 SG_ ObstacleAngle : 0|16@1+ (0.01,-327.68) [-327.68|327.67] "degree"  E115DCU
 SG_ ObstacleAngleStd : 16|16@1+ (0.01,0) [0|327.67] "degree"  E115DCU
 SG_ ObstacleVelXAbs : 32|12@1+ (0.05,-102.4) [-102.4|102.35] "m/sec"  E115DCU
 SG_ ObstacleVelYAbs : 44|12@1+ (0.05,-50) [-50|50] "m/sec"  E115DCU
 SG_ RollingCounter_Obstacle2 : 56|4@1+ (1,0) [0|15] "Counter"  E115DCU
 SG_ Checksum_Obstacle2 : 60|4@1+ (1,0) [0|15] "Counter"  E115DCU

BO_ 1054 ObstacleDataD2: 8 E115DCU
 SG_ ObstaclePosXSTD : 0|13@1+ (0.0625,0) [0|250] "m"  E115DCU
 SG_ ObstaclePosYSTD : 13|13@1+ (0.0625,0) [0|250] "m"  E115DCU
 SG_ ObstacleVelXSTD : 26|12@1+ (0.05,0) [0|102.35] "m/sec"  E115DCU
 SG_ ObstacleVelYSTD : 38|12@1+ (0.05,0) [0|50] "m/sec"  E115DCU
 SG_ ObstacleAccY : 50|10@1+ (0.03,-14.97) [-14.97|14.97] "m/s^2"  E115DCU

BO_ 1053 ObstacleDataC2: 8 E115DCU
 SG_ ObstaclePosX : 0|13@1+ (0.0625,-250) [-250|250] "m"  E115DCU
 SG_ ObstaclePosY : 13|13@1+ (0.0625,-250) [-250|250] "m"  E115DCU
 SG_ ObstacleVelX : 26|12@1+ (0.05,-102.4) [-102.4|102.35] "m/sec"  E115DCU
 SG_ ObstacleVelY : 38|12@1+ (0.05,-50) [-50|50] "m/sec"  E115DCU
 SG_ ObstacleAccX : 50|10@1+ (0.03,-14.97) [-14.97|14.97] "m/s^2"  E115DCU

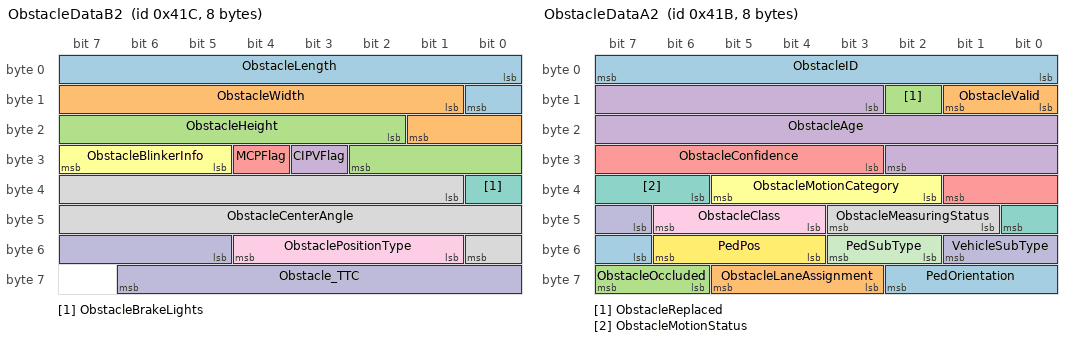
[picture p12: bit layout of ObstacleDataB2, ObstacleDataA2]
BO_ 1052 ObstacleDataB2: 8 E115DCU
 SG_ ObstacleLength : 0|9@1+ (0.05,0) [0|25.6] "m"  E115DCU
 SG_ ObstacleWidth : 9|9@1+ (0.02,0) [0|10.24] "m"  E115DCU
 SG_ ObstacleHeight : 18|9@1+ (0.02,0) [0|10.24] "m"  E115DCU
 SG_ CIPVFlag : 27|1@1+ (1,0) [0|1] "bool"  E115DCU
 SG_ MCPFlag : 28|1@1+ (1,0) [0|1] "bool"  E115DCU
 SG_ ObstacleBlinkerInfo : 29|3@1+ (1,0) [0|4] "Enum"  E115DCU
 SG_ ObstacleBrakeLights : 32|1@1+ (1,0) [0|1] "bool"  E115DCU
 SG_ ObstacleCenterAngle : 33|16@1+ (0.01,-327.68) [-327.68|327.67] "degree"  E115DCU
 SG_ ObstaclePositionType : 49|4@1+ (1,0) [0|9] "Enum"  E115DCU
 SG_ Obstacle_TTC : 53|10@1+ (0.01,0) [0|10] "sec"  E115DCU

BO_ 1051 ObstacleDataA2: 8 E115DCU
 SG_ ObstacleID : 0|8@1+ (1,0) [0|255] "Counter"  E115DCU
 SG_ ObstacleValid : 8|2@1+ (1,0) [0|2] "Enum"  E115DCU
 SG_ ObstacleReplaced : 10|1@1+ (1,0) [0|1] "bool"  E115DCU
 SG_ ObstacleAge : 11|16@1+ (1,0) [0|65535] "Counter"  E115DCU
 SG_ ObstacleConfidence : 27|7@1+ (1,0) [0|100] "prob"  E115DCU
 SG_ ObstacleMotionCategory : 34|4@1+ (1,0) [0|13] "Enum"  E115DCU
 SG_ ObstacleMotionStatus : 38|3@1+ (1,0) [0|7] "Enum"  E115DCU
 SG_ ObstacleMeasuringStatus : 41|3@1+ (1,0) [0|7] "Enum"  E115DCU
 SG_ ObstacleClass : 44|3@1+ (1,0) [0|7] "Enum"  E115DCU
 SG_ VehicleSubType : 47|3@1+ (1,0) [0|7] "Enum"  E115DCU
 SG_ PedSubType : 50|2@1+ (1,0) [0|3] "Enum"  E115DCU
 SG_ PedPos : 52|3@1+ (1,0) [0|7] "Enum"  E115DCU
 SG_ PedOrientation : 55|4@1+ (1,0) [0|9] "Enum"  E115DCU
 SG_ ObstacleLaneAssignment : 59|3@1+ (1,0) [0|5] "Enum"  E115DCU
 SG_ ObstacleOccluded : 62|2@1+ (1,0) [0|3] "Enum"  E115DCU

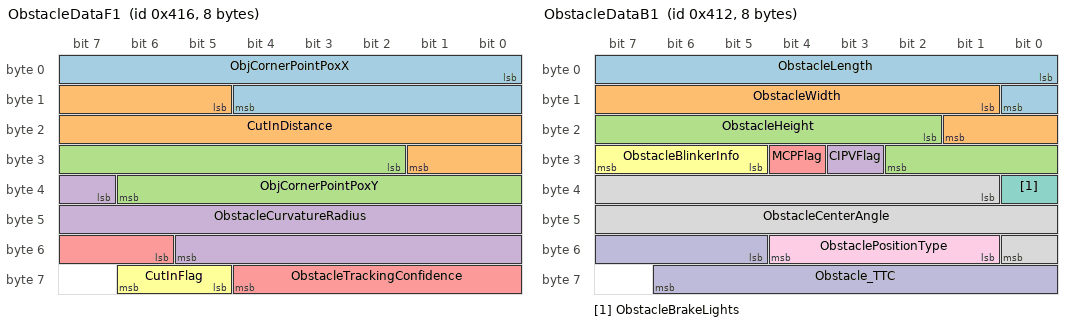
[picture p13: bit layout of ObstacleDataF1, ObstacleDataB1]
BO_ 1046 ObstacleDataF1: 8 Vector__XXX
 SG_ ObjCornerPointPoxX : 0|13@1+ (0.0625,-250) [-250|250] "m" Vector__XXX
 SG_ CutInDistance : 13|13@1+ (0.01,-40.96) [-40.96|40.95] "m" Vector__XXX
 SG_ ObjCornerPointPoxY : 26|13@1+ (0.0625,-250) [-250|250] "m" Vector__XXX
 SG_ ObstacleCurvatureRadius : 39|15@1+ (1,-9999) [-9999|9999] "m" Vector__XXX
 SG_ ObstacleTrackingConfidence : 54|7@1+ (1,0) [0|100] "prob" Vector__XXX
 SG_ CutInFlag : 61|2@1+ (1,0) [0|2] "Enum" Vector__XXX

BO_ 1045 ObstacleDataE1: 8 E115DCU
 SG_ ObstacleAngle : 0|16@1+ (0.01,-327.68) [-327.68|327.67] "degree"  E115DCU
 SG_ ObstacleAngleStd : 16|16@1+ (0.01,0) [0|327.67] "degree"  E115DCU
 SG_ ObstacleVelXAbs : 32|12@1+ (0.05,-102.4) [-102.4|102.35] "m/sec"  E115DCU
 SG_ ObstacleVelYAbs : 44|12@1+ (0.05,-50) [-50|50] "m/sec"  E115DCU
 SG_ RollingCounter_Obstacle1 : 56|4@1+ (1,0) [0|15] "Counter"  E115DCU
 SG_ Checksum_Obstacle1 : 60|4@1+ (1,0) [0|15] "Counter"  E115DCU

BO_ 1044 ObstacleDataD1: 8 E115DCU
 SG_ ObstaclePosXSTD : 0|13@1+ (0.0625,0) [0|250] "m"  E115DCU
 SG_ ObstaclePosYSTD : 13|13@1+ (0.0625,0) [0|250] "m"  E115DCU
 SG_ ObstacleVelXSTD : 26|12@1+ (0.05,0) [0|102.35] "m/sec"  E115DCU
 SG_ ObstacleVelYSTD : 38|12@1+ (0.05,0) [0|50] "m/sec"  E115DCU
 SG_ ObstacleAccY : 50|10@1+ (0.03,-14.97) [-14.97|14.97] "m/s^2"  E115DCU

BO_ 1043 ObstacleDataC1: 8 E115DCU
 SG_ ObstaclePosX : 0|13@1+ (0.0625,-250) [-250|250] "m"  E115DCU
 SG_ ObstaclePosY : 13|13@1+ (0.0625,-250) [-250|250] "m"  E115DCU
 SG_ ObstacleVelX : 26|12@1+ (0.05,-102.4) [-102.4|102.35] "m/sec"  E115DCU
 SG_ ObstacleVelY : 38|12@1+ (0.05,-50) [-50|50] "m/sec"  E115DCU
 SG_ ObstacleAccX : 50|10@1+ (0.03,-14.97) [-14.97|14.97] "m/s^2"  E115DCU

BO_ 1042 ObstacleDataB1: 8 E115DCU
 SG_ ObstacleLength : 0|9@1+ (0.05,0) [0|25.6] "m"  E115DCU
 SG_ ObstacleWidth : 9|9@1+ (0.02,0) [0|10.24] "m"  E115DCU
 SG_ ObstacleHeight : 18|9@1+ (0.02,0) [0|10.24] "m"  E115DCU
 SG_ CIPVFlag : 27|1@1+ (1,0) [0|1] "bool"  E115DCU
 SG_ MCPFlag : 28|1@1+ (1,0) [0|1] "bool"  E115DCU
 SG_ ObstacleBlinkerInfo : 29|3@1+ (1,0) [0|4] "Enum"  E115DCU
 SG_ ObstacleBrakeLights : 32|1@1+ (1,0) [0|1] "bool"  E115DCU
 SG_ ObstacleCenterAngle : 33|16@1+ (0.01,-327.68) [-327.68|327.67] "degree"  E115DCU
 SG_ ObstaclePositionType : 49|4@1+ (1,0) [0|9] "Enum"  E115DCU
 SG_ Obstacle_TTC : 53|10@1+ (0.01,0) [0|10] "sec"  E115DCU

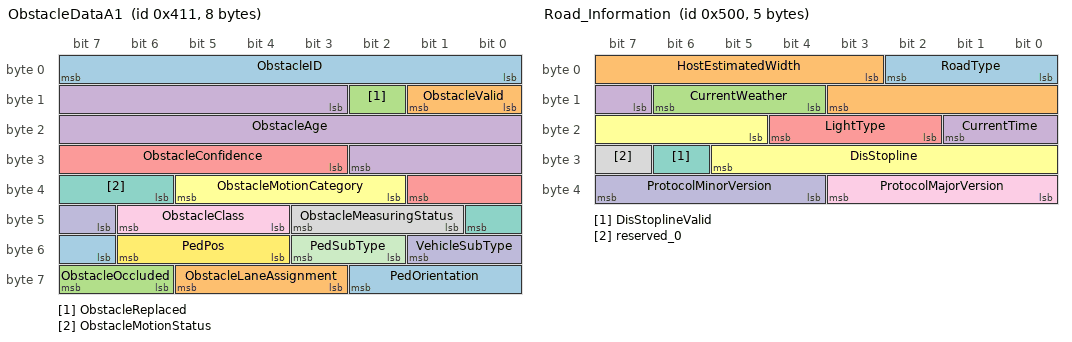
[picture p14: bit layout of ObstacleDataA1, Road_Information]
BO_ 1041 ObstacleDataA1: 8 E115DCU
 SG_ ObstacleID : 0|8@1+ (1,0) [0|255] "Counter"  E115DCU
 SG_ ObstacleValid : 8|2@1+ (1,0) [0|2] "Enum"  E115DCU
 SG_ ObstacleReplaced : 10|1@1+ (1,0) [0|1] "bool"  E115DCU
 SG_ ObstacleAge : 11|16@1+ (1,0) [0|65535] "Counter"  E115DCU
 SG_ ObstacleConfidence : 27|7@1+ (1,0) [0|100] "prob"  E115DCU
 SG_ ObstacleMotionCategory : 34|4@1+ (1,0) [0|13] "Enum"  E115DCU
 SG_ ObstacleMotionStatus : 38|3@1+ (1,0) [0|7] "Enum"  E115DCU
 SG_ ObstacleMeasuringStatus : 41|3@1+ (1,0) [0|7] "Enum"  E115DCU
 SG_ ObstacleClass : 44|3@1+ (1,0) [0|7] "Enum"  E115DCU
 SG_ VehicleSubType : 47|3@1+ (1,0) [0|7] "Enum"  E115DCU
 SG_ PedSubType : 50|2@1+ (1,0) [0|3] "Enum"  E115DCU
 SG_ PedPos : 52|3@1+ (1,0) [0|7] "Enum"  E115DCU
 SG_ PedOrientation : 55|4@1+ (1,0) [0|9] "Enum"  E115DCU
 SG_ ObstacleLaneAssignment : 59|3@1+ (1,0) [0|5] "Enum"  E115DCU
 SG_ ObstacleOccluded : 62|2@1+ (1,0) [0|3] "Enum"  E115DCU

BO_ 1250 ObstacleInternalID1920: 8 Vector__XXX
 SG_ Obstacle_Internal_ID19 : 0|32@1+ (1,0) [0|4294967295] "Counter" Vector__XXX
 SG_ Obstacle_Internal_ID20 : 32|32@1+ (1,0) [0|4294967295] "Counter" Vector__XXX

BO_ 1249 ObstacleInternalID1718: 8 Vector__XXX
 SG_ Obstacle_Internal_ID17 : 0|32@1+ (1,0) [0|4294967295] "Counter" Vector__XXX
 SG_ Obstacle_Internal_ID18 : 32|32@1+ (1,0) [0|4294967295] "Counter" Vector__XXX

BO_ 1248 ObstacleInternalID1516: 8 Vector__XXX
 SG_ Obstacle_Internal_ID15 : 0|32@1+ (1,0) [0|4294967295] "Counter" Vector__XXX
 SG_ Obstacle_Internal_ID16 : 32|32@1+ (1,0) [0|4294967295] "Counter" Vector__XXX

BO_ 1247 ObstacleInternalID1314: 8 Vector__XXX
 SG_ Obstacle_Internal_ID13 : 0|32@1+ (1,0) [0|4294967295] "Counter" Vector__XXX
 SG_ Obstacle_Internal_ID14 : 32|32@1+ (1,0) [0|4294967295] "Counter" Vector__XXX

BO_ 1246 ObstacleInternalID1112: 8 Vector__XXX
 SG_ Obstacle_Internal_ID11 : 0|32@1+ (1,0) [0|4294967295] "Counter" Vector__XXX
 SG_ Obstacle_Internal_ID12 : 32|32@1+ (1,0) [0|4294967295] "Counter" Vector__XXX

BO_ 1245 ObstacleInternalID90: 8 Vector__XXX
 SG_ Obstacle_Internal_ID9 : 0|32@1+ (1,0) [0|4294967295] "Counter" Vector__XXX
 SG_ Obstacle_Internal_ID10 : 32|32@1+ (1,0) [0|4294967295] "Counter" Vector__XXX

BO_ 1244 ObstacleInternalID78: 8 Vector__XXX
 SG_ Obstacle_Internal_ID7 : 0|32@1+ (1,0) [0|4294967295] "Counter" Vector__XXX
 SG_ Obstacle_Internal_ID8 : 32|32@1+ (1,0) [0|4294967295] "Counter" Vector__XXX

BO_ 1243 ObstacleInternalID56: 8 Vector__XXX
 SG_ Obstacle_Internal_ID5 : 0|32@1+ (1,0) [0|4294967295] "Counter" Vector__XXX
 SG_ Obstacle_Internal_ID6 : 32|32@1+ (1,0) [0|4294967295] "Counter" Vector__XXX

BO_ 1242 ObstacleInternalID34: 8 Vector__XXX
 SG_ Obstacle_Internal_ID3 : 0|32@1+ (1,0) [0|4294967295] "Counter" Vector__XXX
 SG_ Obstacle_Internal_ID4 : 32|32@1+ (1,0) [0|4294967295] "Counter" Vector__XXX

BO_ 1241 ObstacleInternalID12: 8 Vector__XXX
 SG_ Obstacle_Internal_ID1 : 0|32@1+ (1,0) [0|4294967295] "Counter" Vector__XXX
 SG_ Obstacle_Internal_ID2 : 32|32@1+ (1,0) [0|4294967295] "Counter" Vector__XXX

BO_ 1279 ObstacleCRC: 8 E115DCU
 SG_ RollingCounter_Obstacle : 0|4@1+ (1,0) [0|15] "Counter"  E115DCU
 SG_ reserved_0 : 4|4@1+ (1,0) [0|15] "NA"  E115DCU
 SG_ CRCChecksum_Obstacle : 8|32@1+ (1,0) [0|4294967295] "Counter"  E115DCU

BO_ 1280 Road_Information: 5 Vector__XXX
 SG_ RoadType : 0|3@1+ (1,0) [0|7] "Enum" Vector__XXX
 SG_ HostEstimatedWidth : 3|9@1+ (0.01,0) [0|4] "meter" Vector__XXX
 SG_ CurrentWeather : 12|3@1+ (1,0) [0|7] "Enum" Vector__XXX
 SG_ CurrentTime : 15|3@1+ (1,0) [0|7] "Enum" Vector__XXX
 SG_ LightType : 18|3@1+ (1,0) [0|7] "Enum" Vector__XXX
 SG_ DisStopline : 21|9@1+ (0.1,-10) [-10|40] "meter" Vector__XXX
 SG_ DisStoplineValid : 30|1@1+ (1,0) [0|1] "bool" Vector__XXX
 SG_ reserved_0 : 31|1@1+ (1,0) [0|15] "NA" Vector__XXX
 SG_ ProtocolMajorVersion : 32|4@1+ (1,0) [0|15] "Counter" Vector__XXX
 SG_ ProtocolMinorVersion : 36|4@1+ (1,0) [0|15] "Counter" Vector__XXX

BO_ 1297 Right_Cone_Road_Edge_B: 8 Vector__XXX
 SG_ ConeRoadEdgeModelC0 : 0|11@1- (0.01,0) [-10|10] "meter" Vector__XXX
 SG_ ConeRoadEdgeModelC1 : 11|11@1- (0.0009765625,0) [-1|0.9990234375] "rad" Vector__XXX
 SG_ ConeRoadEdgeModelC2 : 22|16@1- (9.77E-007,0) [-0.032|0.032] "1/meter" Vector__XXX
 SG_ ConeRoadEdgeModelC3 : 38|17@1- (3.7252902985E-009,0) [-0.000244140625002496|0.000244136899712198] "1/meter^2" Vector__XXX
 SG_ ConeRoadEdgeTLC : 55|8@1+ (0.01,0) [0|2] "sec" Vector__XXX

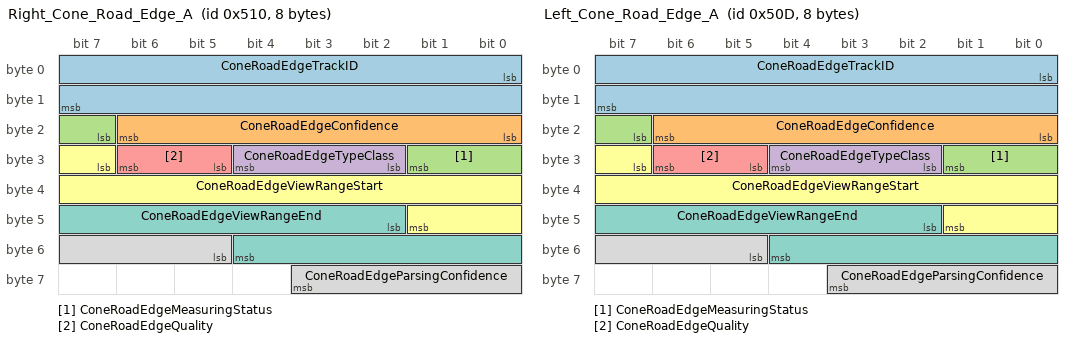
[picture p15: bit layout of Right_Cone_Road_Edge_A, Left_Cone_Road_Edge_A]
BO_ 1296 Right_Cone_Road_Edge_A: 8 Vector__XXX
 SG_ ConeRoadEdgeTrackID : 0|16@1+ (1,0) [0|65535] "Counter" Vector__XXX
 SG_ ConeRoadEdgeConfidence : 16|7@1+ (1,0) [0|100] "prob" Vector__XXX
 SG_ ConeRoadEdgeMeasuringStatus : 23|3@1+ (1,0) [0|7] "Enum" Vector__XXX
 SG_ ConeRoadEdgeTypeClass : 26|3@1+ (1,0) [0|15] "Enum" Vector__XXX
 SG_ ConeRoadEdgeQuality : 29|2@1+ (1,0) [0|3] "Enum" Vector__XXX
 SG_ ConeRoadEdgeViewRangeStart : 31|11@1+ (0.1,0) [0|200] "meter" Vector__XXX
 SG_ ConeRoadEdgeViewRangeEnd : 42|11@1+ (0.1,0) [0|200] "meter" Vector__XXX
 SG_ ConeRoadEdgeParsingConfidence : 53|7@1+ (1,0) [0|100] "prob" Vector__XXX

BO_ 1294 Left_Cone_Road_Edge_B: 8 Vector__XXX
 SG_ ConeRoadEdgeModelC0 : 0|11@1- (0.01,0) [-10|10] "meter" Vector__XXX
 SG_ ConeRoadEdgeModelC1 : 11|11@1- (0.0009765625,0) [-1|0.9990234375] "rad" Vector__XXX
 SG_ ConeRoadEdgeModelC2 : 22|16@1- (9.77E-007,0) [-0.032|0.032] "1/meter" Vector__XXX
 SG_ ConeRoadEdgeModelC3 : 38|17@1- (3.7252902985E-009,0) [-0.000244140625002496|0.000244136899712198] "1/meter^2" Vector__XXX
 SG_ ConeRoadEdgeTLC : 55|8@1+ (0.01,0) [0|2] "sec" Vector__XXX

BO_ 1293 Left_Cone_Road_Edge_A: 8 Vector__XXX
 SG_ ConeRoadEdgeTrackID : 0|16@1+ (1,0) [0|65535] "Counter" Vector__XXX
 SG_ ConeRoadEdgeConfidence : 16|7@1+ (1,0) [0|100] "prob" Vector__XXX
 SG_ ConeRoadEdgeMeasuringStatus : 23|3@1+ (1,0) [0|7] "Enum" Vector__XXX
 SG_ ConeRoadEdgeTypeClass : 26|3@1+ (1,0) [0|15] "Enum" Vector__XXX
 SG_ ConeRoadEdgeQuality : 29|2@1+ (1,0) [0|3] "Enum" Vector__XXX
 SG_ ConeRoadEdgeViewRangeStart : 31|11@1+ (0.1,0) [0|200] "meter" Vector__XXX
 SG_ ConeRoadEdgeViewRangeEnd : 42|11@1+ (0.1,0) [0|200] "meter" Vector__XXX
 SG_ ConeRoadEdgeParsingConfidence : 53|7@1+ (1,0) [0|100] "prob" Vector__XXX

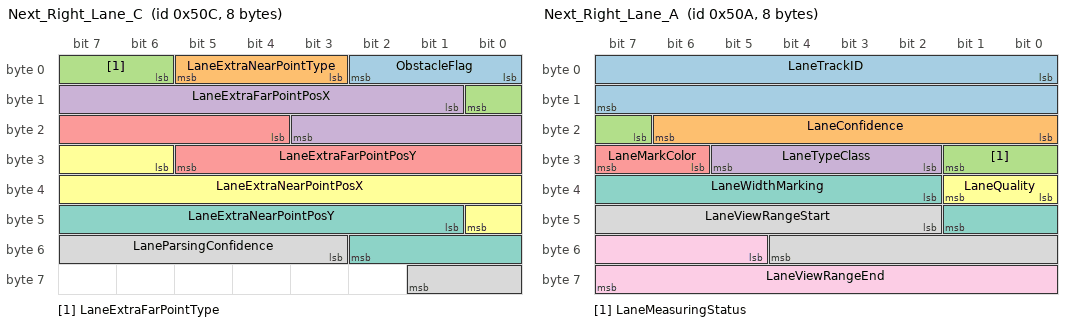
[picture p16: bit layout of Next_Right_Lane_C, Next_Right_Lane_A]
BO_ 1292 Next_Right_Lane_C: 8 Vector__XXX
 SG_ ObstacleFlag : 0|3@1+ (1,0) [0|7] "Enum" Vector__XXX
 SG_ LaneExtraNearPointType : 3|3@1+ (1,0) [0|7] "Enum" Vector__XXX
 SG_ LaneExtraFarPointType : 6|3@1+ (1,0) [0|7] "Enum" Vector__XXX
 SG_ LaneExtraFarPointPosX : 9|11@1+ (0.1,0) [0|204.7] "meter" Vector__XXX
 SG_ LaneExtraFarPointPosY : 20|10@1- (0.1,0) [-51.2|51.1] "meter" Vector__XXX
 SG_ LaneExtraNearPointPosX : 30|11@1+ (0.1,0) [0|204.7] "meter" Vector__XXX
 SG_ LaneExtraNearPointPosY : 41|10@1- (0.1,0) [-51.2|51.1] "meter" Vector__XXX
 SG_ LaneParsingConfidence : 51|7@1+ (1,0) [0|100] "prob" Vector__XXX

BO_ 1291 Next_Right_Lane_B: 8 Vector__XXX
 SG_ LaneModelC0 : 0|11@1- (0.01,0) [-10|10] "meter" Vector__XXX
 SG_ LaneModelC1 : 11|11@1- (0.0009765625,0) [-1|0.9990234375] "rad" Vector__XXX
 SG_ LaneModelC2 : 22|16@1- (9.77E-007,0) [-0.032|0.032] "1/meter" Vector__XXX
 SG_ LaneModelC3 : 38|17@1- (3.7252902985E-009,0) [-0.000244140625002496|0.000244136899712198] "1/meter^2" Vector__XXX

BO_ 1290 Next_Right_Lane_A: 8 Vector__XXX
 SG_ LaneTrackID : 0|16@1+ (1,0) [0|65535] "Counter" Vector__XXX
 SG_ LaneConfidence : 16|7@1+ (1,0) [0|100] "prob" Vector__XXX
 SG_ LaneMeasuringStatus : 23|3@1+ (1,0) [0|7] "Enum" Vector__XXX
 SG_ LaneTypeClass : 26|4@1+ (1,0) [0|15] "Enum" Vector__XXX
 SG_ LaneMarkColor : 30|2@1+ (1,0) [0|3] "Enum" Vector__XXX
 SG_ LaneQuality : 32|2@1+ (1,0) [0|3] "Enum" Vector__XXX
 SG_ LaneWidthMarking : 34|8@1+ (0.01,0) [0|1] "m" Vector__XXX
 SG_ LaneViewRangeStart : 42|11@1+ (0.1,0) [0|200] "meter" Vector__XXX
 SG_ LaneViewRangeEnd : 53|11@1+ (0.1,0) [0|200] "meter" Vector__XXX

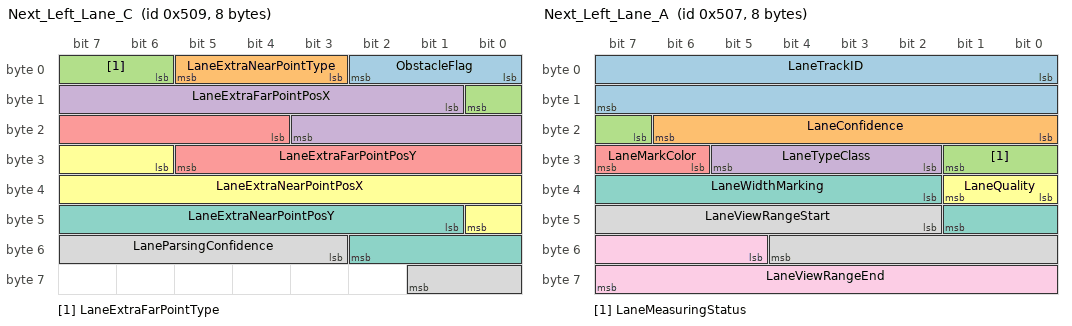
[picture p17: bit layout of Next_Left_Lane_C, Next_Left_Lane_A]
BO_ 1289 Next_Left_Lane_C: 8 Vector__XXX
 SG_ ObstacleFlag : 0|3@1+ (1,0) [0|7] "Enum" Vector__XXX
 SG_ LaneExtraNearPointType : 3|3@1+ (1,0) [0|7] "Enum" Vector__XXX
 SG_ LaneExtraFarPointType : 6|3@1+ (1,0) [0|7] "Enum" Vector__XXX
 SG_ LaneExtraFarPointPosX : 9|11@1+ (0.1,0) [0|204.7] "meter" Vector__XXX
 SG_ LaneExtraFarPointPosY : 20|10@1- (0.1,0) [-51.2|51.1] "meter" Vector__XXX
 SG_ LaneExtraNearPointPosX : 30|11@1+ (0.1,0) [0|204.7] "meter" Vector__XXX
 SG_ LaneExtraNearPointPosY : 41|10@1- (0.1,0) [-51.2|51.1] "meter" Vector__XXX
 SG_ LaneParsingConfidence : 51|7@1+ (1,0) [0|100] "prob" Vector__XXX

BO_ 1288 Next_Left_Lane_B: 8 Vector__XXX
 SG_ LaneModelC0 : 0|11@1- (0.01,0) [-10|10] "meter" Vector__XXX
 SG_ LaneModelC1 : 11|11@1- (0.0009765625,0) [-1|0.9990234375] "rad" Vector__XXX
 SG_ LaneModelC2 : 22|16@1- (9.77E-007,0) [-0.032|0.032] "1/meter" Vector__XXX
 SG_ LaneModelC3 : 38|17@1- (3.7252902985E-009,0) [-0.000244140625002496|0.000244136899712198] "1/meter^2" Vector__XXX

BO_ 1287 Next_Left_Lane_A: 8 Vector__XXX
 SG_ LaneTrackID : 0|16@1+ (1,0) [0|65535] "Counter" Vector__XXX
 SG_ LaneConfidence : 16|7@1+ (1,0) [0|100] "prob" Vector__XXX
 SG_ LaneMeasuringStatus : 23|3@1+ (1,0) [0|7] "Enum" Vector__XXX
 SG_ LaneTypeClass : 26|4@1+ (1,0) [0|15] "Enum" Vector__XXX
 SG_ LaneMarkColor : 30|2@1+ (1,0) [0|3] "Enum" Vector__XXX
 SG_ LaneQuality : 32|2@1+ (1,0) [0|3] "Enum" Vector__XXX
 SG_ LaneWidthMarking : 34|8@1+ (0.01,0) [0|1] "m" Vector__XXX
 SG_ LaneViewRangeStart : 42|11@1+ (0.1,0) [0|200] "meter" Vector__XXX
 SG_ LaneViewRangeEnd : 53|11@1+ (0.1,0) [0|200] "meter" Vector__XXX

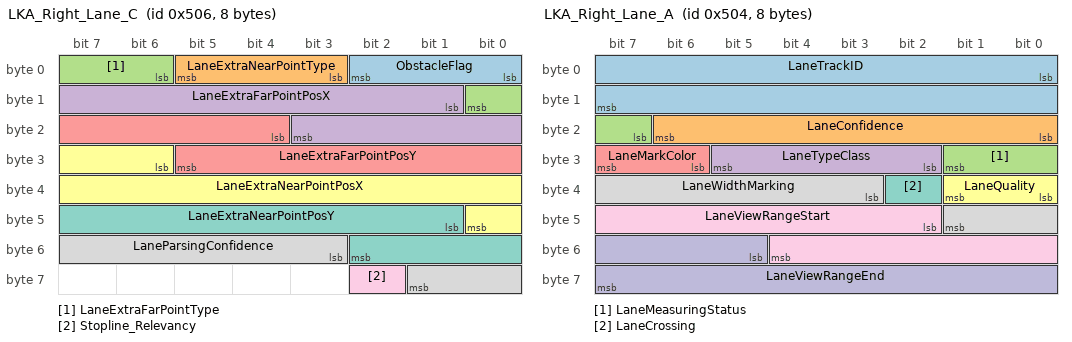
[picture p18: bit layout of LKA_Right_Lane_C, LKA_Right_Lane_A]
BO_ 1286 LKA_Right_Lane_C: 8 Vector__XXX
 SG_ ObstacleFlag : 0|3@1+ (1,0) [0|7] "Enum" Vector__XXX
 SG_ LaneExtraNearPointType : 3|3@1+ (1,0) [0|7] "Enum" Vector__XXX
 SG_ LaneExtraFarPointType : 6|3@1+ (1,0) [0|7] "Enum" Vector__XXX
 SG_ LaneExtraFarPointPosX : 9|11@1+ (0.1,0) [0|204.7] "meter" Vector__XXX
 SG_ LaneExtraFarPointPosY : 20|10@1- (0.1,0) [-51.2|51.1] "meter" Vector__XXX
 SG_ LaneExtraNearPointPosX : 30|11@1+ (0.1,0) [0|204.7] "meter" Vector__XXX
 SG_ LaneExtraNearPointPosY : 41|10@1- (0.1,0) [-51.2|51.1] "meter" Vector__XXX
 SG_ LaneParsingConfidence : 51|7@1+ (1,0) [0|100] "prob" Vector__XXX
 SG_ Stopline_Relevancy : 58|1@1+ (1,0) [0|1] "bool" Vector__XXX

BO_ 1285 LKA_Right_Lane_B: 8 Vector__XXX
 SG_ LaneModelC0 : 0|11@1- (0.01,0) [-10|10] "meter" Vector__XXX
 SG_ LaneModelC1 : 11|11@1- (0.0009765625,0) [-1|0.9990234375] "rad" Vector__XXX
 SG_ LaneModelC2 : 22|16@1- (9.77E-007,0) [-0.032|0.032] "1/meter" Vector__XXX
 SG_ LaneModelC3 : 38|17@1- (3.7252902985E-009,0) [-0.000244140625002496|0.000244136899712198] "1/meter^2" Vector__XXX
 SG_ LaneTLC : 55|8@1+ (0.01,0) [0|2] "sec" Vector__XXX

BO_ 1284 LKA_Right_Lane_A: 8 Vector__XXX
 SG_ LaneTrackID : 0|16@1+ (1,0) [0|65535] "Counter" Vector__XXX
 SG_ LaneConfidence : 16|7@1+ (1,0) [0|100] "prob" Vector__XXX
 SG_ LaneMeasuringStatus : 23|3@1+ (1,0) [0|7] "Enum" Vector__XXX
 SG_ LaneTypeClass : 26|4@1+ (1,0) [0|15] "Enum" Vector__XXX
 SG_ LaneMarkColor : 30|2@1+ (1,0) [0|3] "Enum" Vector__XXX
 SG_ LaneQuality : 32|2@1+ (1,0) [0|3] "Enum" Vector__XXX
 SG_ LaneCrossing : 34|1@1+ (1,0) [0|1] "bool" Vector__XXX
 SG_ LaneWidthMarking : 35|7@1+ (0.01,0) [0|1] "m" Vector__XXX
 SG_ LaneViewRangeStart : 42|11@1+ (0.1,0) [0|200] "meter" Vector__XXX
 SG_ LaneViewRangeEnd : 53|11@1+ (0.1,0) [0|200] "meter" Vector__XXX

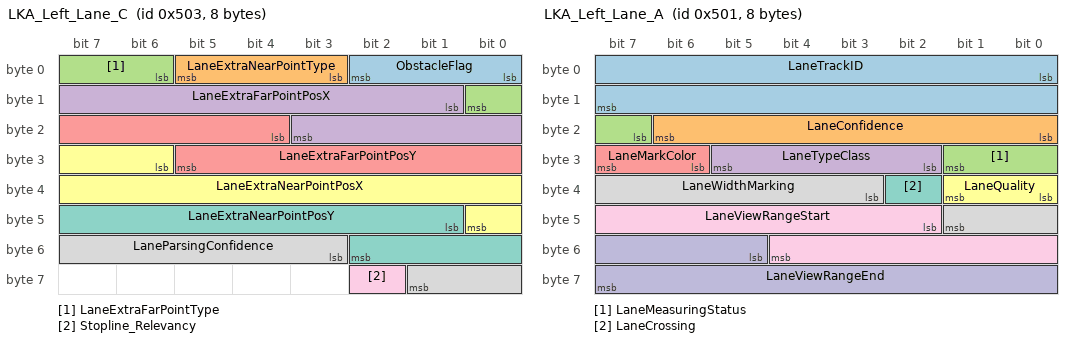
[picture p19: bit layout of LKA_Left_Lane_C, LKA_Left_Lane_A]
BO_ 1283 LKA_Left_Lane_C: 8 Vector__XXX
 SG_ ObstacleFlag : 0|3@1+ (1,0) [0|7] "Enum" Vector__XXX
 SG_ LaneExtraNearPointType : 3|3@1+ (1,0) [0|7] "Enum" Vector__XXX
 SG_ LaneExtraFarPointType : 6|3@1+ (1,0) [0|7] "Enum" Vector__XXX
 SG_ LaneExtraFarPointPosX : 9|11@1+ (0.1,0) [0|204.7] "meter" Vector__XXX
 SG_ LaneExtraFarPointPosY : 20|10@1- (0.1,0) [-51.2|51.1] "meter" Vector__XXX
 SG_ LaneExtraNearPointPosX : 30|11@1+ (0.1,0) [0|204.7] "meter" Vector__XXX
 SG_ LaneExtraNearPointPosY : 41|10@1- (0.1,0) [-51.2|51.1] "meter" Vector__XXX
 SG_ LaneParsingConfidence : 51|7@1+ (1,0) [0|100] "prob" Vector__XXX
 SG_ Stopline_Relevancy : 58|1@1+ (1,0) [0|1] "bool" Vector__XXX

BO_ 1282 LKA_Left_Lane_B: 8 Vector__XXX
 SG_ LaneModelC0 : 0|11@1- (0.01,0) [-10|10] "meter" Vector__XXX
 SG_ LaneModelC1 : 11|11@1- (0.0009765625,0) [-1|0.9990234375] "rad" Vector__XXX
 SG_ LaneModelC2 : 22|16@1- (9.77E-007,0) [-0.032|0.032] "1/meter" Vector__XXX
 SG_ LaneModelC3 : 38|17@1- (3.7252902985E-009,0) [-0.000244140625002496|0.000244136899712198] "1/meter^2" Vector__XXX
 SG_ LaneTLC : 55|8@1+ (0.01,0) [0|2] "sec" Vector__XXX

BO_ 1281 LKA_Left_Lane_A: 8 Vector__XXX
 SG_ LaneTrackID : 0|16@1+ (1,0) [0|65535] "Counter" Vector__XXX
 SG_ LaneConfidence : 16|7@1+ (1,0) [0|100] "prob" Vector__XXX
 SG_ LaneMeasuringStatus : 23|3@1+ (1,0) [0|7] "Enum" Vector__XXX
 SG_ LaneTypeClass : 26|4@1+ (1,0) [0|15] "Enum" Vector__XXX
 SG_ LaneMarkColor : 30|2@1+ (1,0) [0|3] "Enum" Vector__XXX
 SG_ LaneQuality : 32|2@1+ (1,0) [0|3] "Enum" Vector__XXX
 SG_ LaneCrossing : 34|1@1+ (1,0) [0|1] "bool" Vector__XXX
 SG_ LaneWidthMarking : 35|7@1+ (0.01,0) [0|1] "m" Vector__XXX
 SG_ LaneViewRangeStart : 42|11@1+ (0.1,0) [0|200] "meter" Vector__XXX
 SG_ LaneViewRangeEnd : 53|11@1+ (0.1,0) [0|200] "meter" Vector__XXX

BO_ 1311 LaneCRC: 5 Vector__XXX
 SG_ RollingCounter_Lane : 0|4@1+ (1,0) [0|15] "Counter" Vector__XXX
 SG_ reserved_0 : 4|4@1+ (1,0) [0|15] "NA" Vector__XXX
 SG_ CRCChecksum_Lane : 8|32@1+ (1,0) [0|4294967295] "Counter" Vector__XXX

CM_ SG_ 1131 ObstacleID "Object ID, valid value is 1 to 255, 0 as default. 1 to 200 for vehicle, 201 to 255 for pedestrian";
CM_ SG_ 1131 ObstacleValid "Obstacle Valid info, when target exists, 'ObstacleValid'=1 in first frame, 'ObstacleValid'=2 from second frame";
CM_ SG_ 1131 ObstacleReplaced "Reserved";
CM_ SG_ 1131 ObstacleAge "Frame age of this obstacle exists, because some post-process logic to ensure the tracking status and confidence, in the first frame maybe not be '1'";
CM_ SG_ 1131 ObstacleConfidence "Existence probability of Obstacle, calculated from CNN detection, when > 6 continuously means high conf obstacle target. ";
CM_ SG_ 1131 ObstacleMotionCategory "The signal is based on our estimation of where the target is now relatively to the lanes, its rate of change, and our estimation of where it is going to be within one second. Just valid when 'ObstacleClass'=1, vehicle target";
CM_ SG_ 1131 ObstacleMotionStatus "The target is moving or stopped. Just valid when 'ObstacleClass'=1, vehicle target";
CM_ SG_ 1131 ObstacleMeasuringStatus "Were measurements predicted, old, or not valid, 'PREDICTED' will be continuously less than 3 frames";
CM_ SG_ 1131 ObstacleClass "Classification of this object";
CM_ SG_ 1131 VehicleSubType "Vehicle Sub type, when 'ObstacleClass'=1";
CM_ SG_ 1131 PedSubType "Pedestrian Sub type, when 'ObstacleClass'=2";
CM_ SG_ 1131 PedPos "Pedestrian posture, for normal standing person, output as 'Pedestrian'. For cyclist, no further posture could be classificated";
CM_ SG_ 1131 PedOrientation "Pedestrian orientation, classification in single frame in image space";
CM_ SG_ 1131 ObstacleLaneAssignment "Obstacle Lane Assignment £¨Which lane a vehicle belongs to£©";
CM_ SG_ 1131 ObstacleOccluded "Obstacle is occluded or not in image space. Just when the obstacle was partially occluded could output as 2";
CM_ SG_ 1126 ObjCornerPointPoxX "The longitudinal distance of the obstacle's nearest coner to host vehicle in VCS. Most situation the corner point is the potential cut-in frontal corner point. Not valid for cyclist and pedestrian";
CM_ SG_ 1126 CutInDistance "The lateral relative distance of the obstacle's nearest coner to host lane line center. Positive means the vehicle now out of host lane, negative means the vehicle had been part in host lane. Not valid for cyclist and pedestrian";
CM_ SG_ 1126 ObjCornerPointPoxY "The lateral distance of the obstacle's nearest coner to host vehicle in VCS. Most situation the corner point is the potential cut-in frontal corner point. Not valid for cyclist and pedestrian";
CM_ SG_ 1126 ObstacleCurvatureRadius "Curvature radius of obstacle, the tendency of turning, calculated by single frame, mainly used when fusion with Radar";
CM_ SG_ 1126 ObstacleTrackingConfidence "Obstacle Tracking Confidence, which judged the confidence of tracking status.";
CM_ SG_ 1126 CutInFlag "Cut-in status for obstacle. Normal target output as 0; when made cut-in-hostlane action continuously output as 1; when target appeared from edge of FOV and target only partially visible output as 2. Not valid for cyclist and pedestrian";
CM_ SG_ 1125 ObstacleAngle "The heading angle of vehicle or cyclist, not valid pedestrian";
CM_ SG_ 1125 ObstacleAngleStd "The standard deviation of heading angle of obstacle, calculated from Tracking Filter";
CM_ SG_ 1125 ObstacleVelXAbs "The abusolute longitude velocity of the obstacle. ";
CM_ SG_ 1125 ObstacleVelYAbs "The abusolute lateral velocity of the obstacle. ";
CM_ SG_ 1125 RollingCounter_Obstacle9 "Rolling Counter of the msg ObstacleDataA9~ObstacleDataF9, Rolling between 0 and 15 SPI frame by SPI frame";
CM_ SG_ 1125 Checksum_Obstacle9 "CRC Checksum of the msg ObstacleDataA9~ObstacleDataF9, all the signals except Checksum_Obstacle_Signal are included. CRC4 algorithm.";
CM_ SG_ 1124 ObstaclePosXSTD "the standard deviation of longitudinal distance (ObstaclePosX) to observation point of obstacle in VCS, calculated from Tracking Filter";
CM_ SG_ 1124 ObstaclePosYSTD "the standard deviation of lateral distance (ObstaclePosY) to observation point of obstacle in VCS, calculated from Tracking Filter  ";
CM_ SG_ 1124 ObstacleVelXSTD "the standard deviation of longitude velocity (ObstacleVelX) of the obstacle, calculated from Tracking Filter  ";
CM_ SG_ 1124 ObstacleVelYSTD "the standard deviation of  lateral velocity (ObstacleVelY) of the obstacle, calculated from Tracking Filter  ";
CM_ SG_ 1124 ObstacleAccY "The lateral absolute acceleration of the object.";
CM_ SG_ 1123 ObstaclePosX "The longitudinal distance to observation point of obstacle in VCS";
CM_ SG_ 1123 ObstaclePosY "The lateral distance to observation point of obstacle in VCS, left positive, right negative";
CM_ SG_ 1123 ObstacleVelX "The relative longitude velocity of the obstacle and host vehicle";
CM_ SG_ 1123 ObstacleVelY "The relative lateral velocity of the obstacle and host vehicle, left positive, right negative";
CM_ SG_ 1123 ObstacleAccX "The longitude absolute acceleration of the object.";
CM_ SG_ 1122 ObstacleLength "Length of obstacle, valid for vehicle and cyclist. For pedestrian output as 0.";
CM_ SG_ 1122 ObstacleWidth "Width of obstacle rear, valid for vehicle and cyclist. For pedestrian output as 0.";
CM_ SG_ 1122 ObstacleHeight "Height of obstacle, valid for vehicle, cyclist and pedestrian";
CM_ SG_ 1122 CIPVFlag "If this obstacle CIPV, closest target(vehicle and cyclist) in path. Calculated by fusion of host lane path and predicted path";
CM_ SG_ 1122 MCPFlag "If this obstacle MCP, most critical target(pedestrian). Calculated by fusion of host lane path and predicted path";
CM_ SG_ 1122 ObstacleBlinkerInfo "Turn light signal in single frame, just valid for vehicle target. ";
CM_ SG_ 1122 ObstacleBrakeLights "Brake light signal in single frame, just valid for vehicle target";
CM_ SG_ 1122 ObstacleCenterAngle "The Angle Between the orientation of Host Vehicle and the orientation from the front center of Host Vehicle  to the Reference Point of the target. Mainly used when fusion with front Radar";
CM_ SG_ 1122 ObstaclePositionType "Observation point type of the obstacle, mainly depending on the heading angle of the obstacle. For preceding or oncoming target, output as 2; for crossing or turning target, output as 7 or 8. Just valid for vehicle target";
CM_ SG_ 1122 Obstacle_TTC "eTTC value for this obstacle, calculated from target perception distance, velocity and deceleration, by the method of enhanced TTC";
CM_ SG_ 1121 ObstacleID "Object ID, valid value is 1 to 255, 0 as default. 1 to 200 for vehicle, 201 to 255 for pedestrian";
CM_ SG_ 1121 ObstacleValid "Obstacle Valid info, when target exists, 'ObstacleValid'=1 in first frame, 'ObstacleValid'=2 from second frame";
CM_ SG_ 1121 ObstacleReplaced "Reserved";
CM_ SG_ 1121 ObstacleAge "Frame age of this obstacle exists, because some post-process logic to ensure the tracking status and confidence, in the first frame maybe not be '1'";
CM_ SG_ 1121 ObstacleConfidence "Existence probability of Obstacle, calculated from CNN detection, when > 6 continuously means high conf obstacle target. ";
CM_ SG_ 1121 ObstacleMotionCategory "The signal is based on our estimation of where the target is now relatively to the lanes, its rate of change, and our estimation of where it is going to be within one second. Just valid when 'ObstacleClass'=1, vehicle target";
CM_ SG_ 1121 ObstacleMotionStatus "The target is moving or stopped. Just valid when 'ObstacleClass'=1, vehicle target";
CM_ SG_ 1121 ObstacleMeasuringStatus "Were measurements predicted, old, or not valid, 'PREDICTED' will be continuously less than 3 frames";
CM_ SG_ 1121 ObstacleClass "Classification of this object";
CM_ SG_ 1121 VehicleSubType "Vehicle Sub type, when 'ObstacleClass'=1";
CM_ SG_ 1121 PedSubType "Pedestrian Sub type, when 'ObstacleClass'=2";
CM_ SG_ 1121 PedPos "Pedestrian posture, for normal standing person, output as 'Pedestrian'. For cyclist, no further posture could be classificated";
CM_ SG_ 1121 PedOrientation "Pedestrian orientation, classification in single frame in image space";
CM_ SG_ 1121 ObstacleLaneAssignment "Obstacle Lane Assignment £¨Which lane a vehicle belongs to£©";
CM_ SG_ 1121 ObstacleOccluded "Obstacle is occluded or not in image space. Just when the obstacle was partially occluded could output as 2";
CM_ SG_ 1116 ObjCornerPointPoxX "The longitudinal distance of the obstacle's nearest coner to host vehicle in VCS. Most situation the corner point is the potential cut-in frontal corner point. Not valid for cyclist and pedestrian";
CM_ SG_ 1116 CutInDistance "The lateral relative distance of the obstacle's nearest coner to host lane line center. Positive means the vehicle now out of host lane, negative means the vehicle had been part in host lane. Not valid for cyclist and pedestrian";
CM_ SG_ 1116 ObjCornerPointPoxY "The lateral distance of the obstacle's nearest coner to host vehicle in VCS. Most situation the corner point is the potential cut-in frontal corner point. Not valid for cyclist and pedestrian";
CM_ SG_ 1116 ObstacleCurvatureRadius "Curvature radius of obstacle, the tendency of turning, calculated by single frame, mainly used when fusion with Radar";
CM_ SG_ 1116 ObstacleTrackingConfidence "Obstacle Tracking Confidence, which judged the confidence of tracking status.";
CM_ SG_ 1116 CutInFlag "Cut-in status for obstacle. Normal target output as 0; when made cut-in-hostlane action continuously output as 1; when target appeared from edge of FOV and target only partially visible output as 2. Not valid for cyclist and pedestrian";
CM_ SG_ 1115 ObstacleAngle "The heading angle of vehicle or cyclist, not valid pedestrian";
CM_ SG_ 1115 ObstacleAngleStd "The standard deviation of heading angle of obstacle, calculated from Tracking Filter";
CM_ SG_ 1115 ObstacleVelXAbs "The abusolute longitude velocity of the obstacle. ";
CM_ SG_ 1115 ObstacleVelYAbs "The abusolute lateral velocity of the obstacle. ";
CM_ SG_ 1115 RollingCounter_Obstacle8 "Rolling Counter of the msg ObstacleDataA8~ObstacleDataF8, Rolling between 0 and 15 SPI frame by SPI frame";
CM_ SG_ 1115 Checksum_Obstacle8 "CRC Checksum of the msg ObstacleDataA8~ObstacleDataF8, all the signals except Checksum_Obstacle_Signal are included. CRC4 algorithm.";
CM_ SG_ 1114 ObstaclePosXSTD "the standard deviation of longitudinal distance (ObstaclePosX) to observation point of obstacle in VCS, calculated from Tracking Filter";
CM_ SG_ 1114 ObstaclePosYSTD "the standard deviation of lateral distance (ObstaclePosY) to observation point of obstacle in VCS, calculated from Tracking Filter  ";
CM_ SG_ 1114 ObstacleVelXSTD "the standard deviation of longitude velocity (ObstacleVelX) of the obstacle, calculated from Tracking Filter  ";
CM_ SG_ 1114 ObstacleVelYSTD "the standard deviation of  lateral velocity (ObstacleVelY) of the obstacle, calculated from Tracking Filter  ";
CM_ SG_ 1114 ObstacleAccY "The lateral absolute acceleration of the object.";
CM_ SG_ 1113 ObstaclePosX "The longitudinal distance to observation point of obstacle in VCS";
CM_ SG_ 1113 ObstaclePosY "The lateral distance to observation point of obstacle in VCS, left positive, right negative";
CM_ SG_ 1113 ObstacleVelX "The relative longitude velocity of the obstacle and host vehicle";
CM_ SG_ 1113 ObstacleVelY "The relative lateral velocity of the obstacle and host vehicle, left positive, right negative";
CM_ SG_ 1113 ObstacleAccX "The longitude absolute acceleration of the object.";
CM_ SG_ 1112 ObstacleLength "Length of obstacle, valid for vehicle and cyclist. For pedestrian output as 0.";
CM_ SG_ 1112 ObstacleWidth "Width of obstacle rear, valid for vehicle and cyclist. For pedestrian output as 0.";
CM_ SG_ 1112 ObstacleHeight "Height of obstacle, valid for vehicle, cyclist and pedestrian";
CM_ SG_ 1112 CIPVFlag "If this obstacle CIPV, closest target(vehicle and cyclist) in path. Calculated by fusion of host lane path and predicted path";
CM_ SG_ 1112 MCPFlag "If this obstacle MCP, most critical target(pedestrian). Calculated by fusion of host lane path and predicted path";
CM_ SG_ 1112 ObstacleBlinkerInfo "Turn light signal in single frame, just valid for vehicle target. ";
CM_ SG_ 1112 ObstacleBrakeLights "Brake light signal in single frame, just valid for vehicle target";
CM_ SG_ 1112 ObstacleCenterAngle "The Angle Between the orientation of Host Vehicle and the orientation from the front center of Host Vehicle  to the Reference Point of the target. Mainly used when fusion with front Radar";
CM_ SG_ 1112 ObstaclePositionType "Observation point type of the obstacle, mainly depending on the heading angle of the obstacle. For preceding or oncoming target, output as 2; for crossing or turning target, output as 7 or 8. Just valid for vehicle target";
CM_ SG_ 1112 Obstacle_TTC "eTTC value for this obstacle, calculated from target perception distance, velocity and deceleration, by the method of enhanced TTC";
CM_ SG_ 1111 ObstacleID "Object ID, valid value is 1 to 255, 0 as default. 1 to 200 for vehicle, 201 to 255 for pedestrian";
CM_ SG_ 1111 ObstacleValid "Obstacle Valid info, when target exists, 'ObstacleValid'=1 in first frame, 'ObstacleValid'=2 from second frame";
CM_ SG_ 1111 ObstacleReplaced "Reserved";
CM_ SG_ 1111 ObstacleAge "Frame age of this obstacle exists, because some post-process logic to ensure the tracking status and confidence, in the first frame maybe not be '1'";
CM_ SG_ 1111 ObstacleConfidence "Existence probability of Obstacle, calculated from CNN detection, when > 6 continuously means high conf obstacle target. ";
CM_ SG_ 1111 ObstacleMotionCategory "The signal is based on our estimation of where the target is now relatively to the lanes, its rate of change, and our estimation of where it is going to be within one second. Just valid when 'ObstacleClass'=1, vehicle target";
CM_ SG_ 1111 ObstacleMotionStatus "The target is moving or stopped. Just valid when 'ObstacleClass'=1, vehicle target";
CM_ SG_ 1111 ObstacleMeasuringStatus "Were measurements predicted, old, or not valid, 'PREDICTED' will be continuously less than 3 frames";
CM_ SG_ 1111 ObstacleClass "Classification of this object";
CM_ SG_ 1111 VehicleSubType "Vehicle Sub type, when 'ObstacleClass'=1";
CM_ SG_ 1111 PedSubType "Pedestrian Sub type, when 'ObstacleClass'=2";
CM_ SG_ 1111 PedPos "Pedestrian posture, for normal standing person, output as 'Pedestrian'. For cyclist, no further posture could be classificated";
CM_ SG_ 1111 PedOrientation "Pedestrian orientation, classification in single frame in image space";
CM_ SG_ 1111 ObstacleLaneAssignment "Obstacle Lane Assignment £¨Which lane a vehicle belongs to£©";
CM_ SG_ 1111 ObstacleOccluded "Obstacle is occluded or not in image space. Just when the obstacle was partially occluded could output as 2";
CM_ SG_ 1106 ObjCornerPointPoxX "The longitudinal distance of the obstacle's nearest coner to host vehicle in VCS. Most situation the corner point is the potential cut-in frontal corner point. Not valid for cyclist and pedestrian";
CM_ SG_ 1106 CutInDistance "The lateral relative distance of the obstacle's nearest coner to host lane line center. Positive means the vehicle now out of host lane, negative means the vehicle had been part in host lane. Not valid for cyclist and pedestrian";
CM_ SG_ 1106 ObjCornerPointPoxY "The lateral distance of the obstacle's nearest coner to host vehicle in VCS. Most situation the corner point is the potential cut-in frontal corner point. Not valid for cyclist and pedestrian";
CM_ SG_ 1106 ObstacleCurvatureRadius "Curvature radius of obstacle, the tendency of turning, calculated by single frame, mainly used when fusion with Radar";
CM_ SG_ 1106 ObstacleTrackingConfidence "Obstacle Tracking Confidence, which judged the confidence of tracking status.";
CM_ SG_ 1106 CutInFlag "Cut-in status for obstacle. Normal target output as 0; when made cut-in-hostlane action continuously output as 1; when target appeared from edge of FOV and target only partially visible output as 2. Not valid for cyclist and pedestrian";
CM_ SG_ 1105 ObstacleAngle "The heading angle of vehicle or cyclist, not valid pedestrian";
CM_ SG_ 1105 ObstacleAngleStd "The standard deviation of heading angle of obstacle, calculated from Tracking Filter";
CM_ SG_ 1105 ObstacleVelXAbs "The abusolute longitude velocity of the obstacle. ";
CM_ SG_ 1105 ObstacleVelYAbs "The abusolute lateral velocity of the obstacle. ";
CM_ SG_ 1105 RollingCounter_Obstacle7 "Rolling Counter of the msg ObstacleDataA7~ObstacleDataF7, Rolling between 0 and 15 SPI frame by SPI frame";
CM_ SG_ 1105 Checksum_Obstacle7 "CRC Checksum of the msg ObstacleDataA7~ObstacleDataF7, all the signals except Checksum_Obstacle_Signal are included. CRC4 algorithm.";
CM_ SG_ 1104 ObstaclePosXSTD "the standard deviation of longitudinal distance (ObstaclePosX) to observation point of obstacle in VCS, calculated from Tracking Filter";
CM_ SG_ 1104 ObstaclePosYSTD "the standard deviation of lateral distance (ObstaclePosY) to observation point of obstacle in VCS, calculated from Tracking Filter  ";
CM_ SG_ 1104 ObstacleVelXSTD "the standard deviation of longitude velocity (ObstacleVelX) of the obstacle, calculated from Tracking Filter  ";
CM_ SG_ 1104 ObstacleVelYSTD "the standard deviation of  lateral velocity (ObstacleVelY) of the obstacle, calculated from Tracking Filter  ";
CM_ SG_ 1104 ObstacleAccY "The lateral absolute acceleration of the object.";
CM_ SG_ 1103 ObstaclePosX "The longitudinal distance to observation point of obstacle in VCS";
CM_ SG_ 1103 ObstaclePosY "The lateral distance to observation point of obstacle in VCS, left positive, right negative";
CM_ SG_ 1103 ObstacleVelX "The relative longitude velocity of the obstacle and host vehicle";
CM_ SG_ 1103 ObstacleVelY "The relative lateral velocity of the obstacle and host vehicle, left positive, right negative";
CM_ SG_ 1103 ObstacleAccX "The longitude absolute acceleration of the object.";
CM_ SG_ 1102 ObstacleLength "Length of obstacle, valid for vehicle and cyclist. For pedestrian output as 0.";
CM_ SG_ 1102 ObstacleWidth "Width of obstacle rear, valid for vehicle and cyclist. For pedestrian output as 0.";
CM_ SG_ 1102 ObstacleHeight "Height of obstacle, valid for vehicle, cyclist and pedestrian";
CM_ SG_ 1102 CIPVFlag "If this obstacle CIPV, closest target(vehicle and cyclist) in path. Calculated by fusion of host lane path and predicted path";
CM_ SG_ 1102 MCPFlag "If this obstacle MCP, most critical target(pedestrian). Calculated by fusion of host lane path and predicted path";
CM_ SG_ 1102 ObstacleBlinkerInfo "Turn light signal in single frame, just valid for vehicle target. ";
CM_ SG_ 1102 ObstacleBrakeLights "Brake light signal in single frame, just valid for vehicle target";
CM_ SG_ 1102 ObstacleCenterAngle "The Angle Between the orientation of Host Vehicle and the orientation from the front center of Host Vehicle  to the Reference Point of the target. Mainly used when fusion with front Radar";
CM_ SG_ 1102 ObstaclePositionType "Observation point type of the obstacle, mainly depending on the heading angle of the obstacle. For preceding or oncoming target, output as 2; for crossing or turning target, output as 7 or 8. Just valid for vehicle target";
CM_ SG_ 1102 Obstacle_TTC "eTTC value for this obstacle, calculated from target perception distance, velocity and deceleration, by the method of enhanced TTC";
CM_ SG_ 1101 ObstacleID "Object ID, valid value is 1 to 255, 0 as default. 1 to 200 for vehicle, 201 to 255 for pedestrian";
CM_ SG_ 1101 ObstacleValid "Obstacle Valid info, when target exists, 'ObstacleValid'=1 in first frame, 'ObstacleValid'=2 from second frame";
CM_ SG_ 1101 ObstacleReplaced "Reserved";
CM_ SG_ 1101 ObstacleAge "Frame age of this obstacle exists, because some post-process logic to ensure the tracking status and confidence, in the first frame maybe not be '1'";
CM_ SG_ 1101 ObstacleConfidence "Existence probability of Obstacle, calculated from CNN detection, when > 6 continuously means high conf obstacle target. ";
CM_ SG_ 1101 ObstacleMotionCategory "The signal is based on our estimation of where the target is now relatively to the lanes, its rate of change, and our estimation of where it is going to be within one second. Just valid when 'ObstacleClass'=1, vehicle target";
CM_ SG_ 1101 ObstacleMotionStatus "The target is moving or stopped. Just valid when 'ObstacleClass'=1, vehicle target";
CM_ SG_ 1101 ObstacleMeasuringStatus "Were measurements predicted, old, or not valid, 'PREDICTED' will be continuously less than 3 frames";
CM_ SG_ 1101 ObstacleClass "Classification of this object";
CM_ SG_ 1101 VehicleSubType "Vehicle Sub type, when 'ObstacleClass'=1";
CM_ SG_ 1101 PedSubType "Pedestrian Sub type, when 'ObstacleClass'=2";
CM_ SG_ 1101 PedPos "Pedestrian posture, for normal standing person, output as 'Pedestrian'. For cyclist, no further posture could be classificated";
CM_ SG_ 1101 PedOrientation "Pedestrian orientation, classification in single frame in image space";
CM_ SG_ 1101 ObstacleLaneAssignment "Obstacle Lane Assignment £¨Which lane a vehicle belongs to£©";
CM_ SG_ 1101 ObstacleOccluded "Obstacle is occluded or not in image space. Just when the obstacle was partially occluded could output as 2";
CM_ SG_ 1096 ObjCornerPointPoxX "The longitudinal distance of the obstacle's nearest coner to host vehicle in VCS. Most situation the corner point is the potential cut-in frontal corner point. Not valid for cyclist and pedestrian";
CM_ SG_ 1096 CutInDistance "The lateral relative distance of the obstacle's nearest coner to host lane line center. Positive means the vehicle now out of host lane, negative means the vehicle had been part in host lane. Not valid for cyclist and pedestrian";
CM_ SG_ 1096 ObjCornerPointPoxY "The lateral distance of the obstacle's nearest coner to host vehicle in VCS. Most situation the corner point is the potential cut-in frontal corner point. Not valid for cyclist and pedestrian";
CM_ SG_ 1096 ObstacleCurvatureRadius "Curvature radius of obstacle, the tendency of turning, calculated by single frame, mainly used when fusion with Radar";
CM_ SG_ 1096 ObstacleTrackingConfidence "Obstacle Tracking Confidence, which judged the confidence of tracking status.";
CM_ SG_ 1096 CutInFlag "Cut-in status for obstacle. Normal target output as 0; when made cut-in-hostlane action continuously output as 1; when target appeared from edge of FOV and target only partially visible output as 2. Not valid for cyclist and pedestrian";
CM_ SG_ 1095 ObstacleAngle "The heading angle of vehicle or cyclist, not valid pedestrian";
CM_ SG_ 1095 ObstacleAngleStd "The standard deviation of heading angle of obstacle, calculated from Tracking Filter";
CM_ SG_ 1095 ObstacleVelXAbs "The abusolute longitude velocity of the obstacle. ";
CM_ SG_ 1095 ObstacleVelYAbs "The abusolute lateral velocity of the obstacle. ";
CM_ SG_ 1095 RollingCounter_Obstacle6 "Rolling Counter of the msg ObstacleDataA6~ObstacleDataF6, Rolling between 0 and 15 SPI frame by SPI frame";
CM_ SG_ 1095 Checksum_Obstacle6 "CRC Checksum of the msg ObstacleDataA6~ObstacleDataF6, all the signals except Checksum_Obstacle_Signal are included. CRC4 algorithm.";
CM_ SG_ 1094 ObstaclePosXSTD "the standard deviation of longitudinal distance (ObstaclePosX) to observation point of obstacle in VCS, calculated from Tracking Filter";
CM_ SG_ 1094 ObstaclePosYSTD "the standard deviation of lateral distance (ObstaclePosY) to observation point of obstacle in VCS, calculated from Tracking Filter  ";
CM_ SG_ 1094 ObstacleVelXSTD "the standard deviation of longitude velocity (ObstacleVelX) of the obstacle, calculated from Tracking Filter  ";
CM_ SG_ 1094 ObstacleVelYSTD "the standard deviation of  lateral velocity (ObstacleVelY) of the obstacle, calculated from Tracking Filter  ";
CM_ SG_ 1094 ObstacleAccY "The lateral absolute acceleration of the object.";
CM_ SG_ 1093 ObstaclePosX "The longitudinal distance to observation point of obstacle in VCS";
CM_ SG_ 1093 ObstaclePosY "The lateral distance to observation point of obstacle in VCS, left positive, right negative";
CM_ SG_ 1093 ObstacleVelX "The relative longitude velocity of the obstacle and host vehicle";
CM_ SG_ 1093 ObstacleVelY "The relative lateral velocity of the obstacle and host vehicle, left positive, right negative";
CM_ SG_ 1093 ObstacleAccX "The longitude absolute acceleration of the object.";
CM_ SG_ 1092 ObstacleLength "Length of obstacle, valid for vehicle and cyclist. For pedestrian output as 0.";
CM_ SG_ 1092 ObstacleWidth "Width of obstacle rear, valid for vehicle and cyclist. For pedestrian output as 0.";
CM_ SG_ 1092 ObstacleHeight "Height of obstacle, valid for vehicle, cyclist and pedestrian";
CM_ SG_ 1092 CIPVFlag "If this obstacle CIPV, closest target(vehicle and cyclist) in path. Calculated by fusion of host lane path and predicted path";
CM_ SG_ 1092 MCPFlag "If this obstacle MCP, most critical target(pedestrian). Calculated by fusion of host lane path and predicted path";
CM_ SG_ 1092 ObstacleBlinkerInfo "Turn light signal in single frame, just valid for vehicle target. ";
CM_ SG_ 1092 ObstacleBrakeLights "Brake light signal in single frame, just valid for vehicle target";
CM_ SG_ 1092 ObstacleCenterAngle "The Angle Between the orientation of Host Vehicle and the orientation from the front center of Host Vehicle  to the Reference Point of the target. Mainly used when fusion with front Radar";
CM_ SG_ 1092 ObstaclePositionType "Observation point type of the obstacle, mainly depending on the heading angle of the obstacle. For preceding or oncoming target, output as 2; for crossing or turning target, output as 7 or 8. Just valid for vehicle target";
CM_ SG_ 1092 Obstacle_TTC "eTTC value for this obstacle, calculated from target perception distance, velocity and deceleration, by the method of enhanced TTC";
CM_ SG_ 1091 ObstacleID "Object ID, valid value is 1 to 255, 0 as default. 1 to 200 for vehicle, 201 to 255 for pedestrian";
CM_ SG_ 1091 ObstacleValid "Obstacle Valid info, when target exists, 'ObstacleValid'=1 in first frame, 'ObstacleValid'=2 from second frame";
CM_ SG_ 1091 ObstacleReplaced "Reserved";
CM_ SG_ 1091 ObstacleAge "Frame age of this obstacle exists, because some post-process logic to ensure the tracking status and confidence, in the first frame maybe not be '1'";
CM_ SG_ 1091 ObstacleConfidence "Existence probability of Obstacle, calculated from CNN detection, when > 6 continuously means high conf obstacle target. ";
CM_ SG_ 1091 ObstacleMotionCategory "The signal is based on our estimation of where the target is now relatively to the lanes, its rate of change, and our estimation of where it is going to be within one second. Just valid when 'ObstacleClass'=1, vehicle target";
CM_ SG_ 1091 ObstacleMotionStatus "The target is moving or stopped. Just valid when 'ObstacleClass'=1, vehicle target";
CM_ SG_ 1091 ObstacleMeasuringStatus "Were measurements predicted, old, or not valid, 'PREDICTED' will be continuously less than 3 frames";
CM_ SG_ 1091 ObstacleClass "Classification of this object";
CM_ SG_ 1091 VehicleSubType "Vehicle Sub type, when 'ObstacleClass'=1";
CM_ SG_ 1091 PedSubType "Pedestrian Sub type, when 'ObstacleClass'=2";
CM_ SG_ 1091 PedPos "Pedestrian posture, for normal standing person, output as 'Pedestrian'. For cyclist, no further posture could be classificated";
CM_ SG_ 1091 PedOrientation "Pedestrian orientation, classification in single frame in image space";
CM_ SG_ 1091 ObstacleLaneAssignment "Obstacle Lane Assignment £¨Which lane a vehicle belongs to£©";
CM_ SG_ 1091 ObstacleOccluded "Obstacle is occluded or not in image space. Just when the obstacle was partially occluded could output as 2";
CM_ SG_ 1086 ObjCornerPointPoxX "The longitudinal distance of the obstacle's nearest coner to host vehicle in VCS. Most situation the corner point is the potential cut-in frontal corner point. Not valid for cyclist and pedestrian";
CM_ SG_ 1086 CutInDistance "The lateral relative distance of the obstacle's nearest coner to host lane line center. Positive means the vehicle now out of host lane, negative means the vehicle had been part in host lane. Not valid for cyclist and pedestrian";
CM_ SG_ 1086 ObjCornerPointPoxY "The lateral distance of the obstacle's nearest coner to host vehicle in VCS. Most situation the corner point is the potential cut-in frontal corner point. Not valid for cyclist and pedestrian";
CM_ SG_ 1086 ObstacleCurvatureRadius "Curvature radius of obstacle, the tendency of turning, calculated by single frame, mainly used when fusion with Radar";
CM_ SG_ 1086 ObstacleTrackingConfidence "Obstacle Tracking Confidence, which judged the confidence of tracking status.";
CM_ SG_ 1086 CutInFlag "Cut-in status for obstacle. Normal target output as 0; when made cut-in-hostlane action continuously output as 1; when target appeared from edge of FOV and target only partially visible output as 2. Not valid for cyclist and pedestrian";
CM_ SG_ 1085 ObstacleAngle "The heading angle of vehicle or cyclist, not valid pedestrian";
CM_ SG_ 1085 ObstacleAngleStd "The standard deviation of heading angle of obstacle, calculated from Tracking Filter";
CM_ SG_ 1085 ObstacleVelXAbs "The abusolute longitude velocity of the obstacle. ";
CM_ SG_ 1085 ObstacleVelYAbs "The abusolute lateral velocity of the obstacle. ";
CM_ SG_ 1085 RollingCounter_Obstacle5 "Rolling Counter of the msg ObstacleDataA5~ObstacleDataF5, Rolling between 0 and 15 SPI frame by SPI frame";
CM_ SG_ 1085 Checksum_Obstacle5 "CRC Checksum of the msg ObstacleDataA5~ObstacleDataF5, all the signals except Checksum_Obstacle_Signal are included. CRC4 algorithm.";
CM_ SG_ 1084 ObstaclePosXSTD "the standard deviation of longitudinal distance (ObstaclePosX) to observation point of obstacle in VCS, calculated from Tracking Filter";
CM_ SG_ 1084 ObstaclePosYSTD "the standard deviation of lateral distance (ObstaclePosY) to observation point of obstacle in VCS, calculated from Tracking Filter  ";
CM_ SG_ 1084 ObstacleVelXSTD "the standard deviation of longitude velocity (ObstacleVelX) of the obstacle, calculated from Tracking Filter  ";
CM_ SG_ 1084 ObstacleVelYSTD "the standard deviation of  lateral velocity (ObstacleVelY) of the obstacle, calculated from Tracking Filter  ";
CM_ SG_ 1084 ObstacleAccY "The lateral absolute acceleration of the object.";
CM_ SG_ 1083 ObstaclePosX "The longitudinal distance to observation point of obstacle in VCS";
CM_ SG_ 1083 ObstaclePosY "The lateral distance to observation point of obstacle in VCS, left positive, right negative";
CM_ SG_ 1083 ObstacleVelX "The relative longitude velocity of the obstacle and host vehicle";
CM_ SG_ 1083 ObstacleVelY "The relative lateral velocity of the obstacle and host vehicle, left positive, right negative";
CM_ SG_ 1083 ObstacleAccX "The longitude absolute acceleration of the object.";
CM_ SG_ 1082 ObstacleLength "Length of obstacle, valid for vehicle and cyclist. For pedestrian output as 0.";
CM_ SG_ 1082 ObstacleWidth "Width of obstacle rear, valid for vehicle and cyclist. For pedestrian output as 0.";
CM_ SG_ 1082 ObstacleHeight "Height of obstacle, valid for vehicle, cyclist and pedestrian";
CM_ SG_ 1082 CIPVFlag "If this obstacle CIPV, closest target(vehicle and cyclist) in path. Calculated by fusion of host lane path and predicted path";
CM_ SG_ 1082 MCPFlag "If this obstacle MCP, most critical target(pedestrian). Calculated by fusion of host lane path and predicted path";
CM_ SG_ 1082 ObstacleBlinkerInfo "Turn light signal in single frame, just valid for vehicle target. ";
CM_ SG_ 1082 ObstacleBrakeLights "Brake light signal in single frame, just valid for vehicle target";
CM_ SG_ 1082 ObstacleCenterAngle "The Angle Between the orientation of Host Vehicle and the orientation from the front center of Host Vehicle  to the Reference Point of the target. Mainly used when fusion with front Radar";
CM_ SG_ 1082 ObstaclePositionType "Observation point type of the obstacle, mainly depending on the heading angle of the obstacle. For preceding or oncoming target, output as 2; for crossing or turning target, output as 7 or 8. Just valid for vehicle target";
CM_ SG_ 1082 Obstacle_TTC "eTTC value for this obstacle, calculated from target perception distance, velocity and deceleration, by the method of enhanced TTC";
CM_ SG_ 1081 ObstacleID "Object ID, valid value is 1 to 255, 0 as default. 1 to 200 for vehicle, 201 to 255 for pedestrian";
CM_ SG_ 1081 ObstacleValid "Obstacle Valid info, when target exists, 'ObstacleValid'=1 in first frame, 'ObstacleValid'=2 from second frame";
CM_ SG_ 1081 ObstacleReplaced "Reserved";
CM_ SG_ 1081 ObstacleAge "Frame age of this obstacle exists, because some post-process logic to ensure the tracking status and confidence, in the first frame maybe not be '1'";
CM_ SG_ 1081 ObstacleConfidence "Existence probability of Obstacle, calculated from CNN detection, when > 6 continuously means high conf obstacle target. ";
CM_ SG_ 1081 ObstacleMotionCategory "The signal is based on our estimation of where the target is now relatively to the lanes, its rate of change, and our estimation of where it is going to be within one second. Just valid when 'ObstacleClass'=1, vehicle target";
CM_ SG_ 1081 ObstacleMotionStatus "The target is moving or stopped. Just valid when 'ObstacleClass'=1, vehicle target";
CM_ SG_ 1081 ObstacleMeasuringStatus "Were measurements predicted, old, or not valid, 'PREDICTED' will be continuously less than 3 frames";
CM_ SG_ 1081 ObstacleClass "Classification of this object";
CM_ SG_ 1081 VehicleSubType "Vehicle Sub type, when 'ObstacleClass'=1";
CM_ SG_ 1081 PedSubType "Pedestrian Sub type, when 'ObstacleClass'=2";
CM_ SG_ 1081 PedPos "Pedestrian posture, for normal standing person, output as 'Pedestrian'. For cyclist, no further posture could be classificated";
CM_ SG_ 1081 PedOrientation "Pedestrian orientation, classification in single frame in image space";
CM_ SG_ 1081 ObstacleLaneAssignment "Obstacle Lane Assignment £¨Which lane a vehicle belongs to£©";
CM_ SG_ 1081 ObstacleOccluded "Obstacle is occluded or not in image space. Just when the obstacle was partially occluded could output as 2";
CM_ SG_ 1076 ObjCornerPointPoxX "The longitudinal distance of the obstacle's nearest coner to host vehicle in VCS. Most situation the corner point is the potential cut-in frontal corner point. Not valid for cyclist and pedestrian";
CM_ SG_ 1076 CutInDistance "The lateral relative distance of the obstacle's nearest coner to host lane line center. Positive means the vehicle now out of host lane, negative means the vehicle had been part in host lane. Not valid for cyclist and pedestrian";
CM_ SG_ 1076 ObjCornerPointPoxY "The lateral distance of the obstacle's nearest coner to host vehicle in VCS. Most situation the corner point is the potential cut-in frontal corner point. Not valid for cyclist and pedestrian";
CM_ SG_ 1076 ObstacleCurvatureRadius "Curvature radius of obstacle, the tendency of turning, calculated by single frame, mainly used when fusion with Radar";
CM_ SG_ 1076 ObstacleTrackingConfidence "Obstacle Tracking Confidence, which judged the confidence of tracking status.";
CM_ SG_ 1076 CutInFlag "Cut-in status for obstacle. Normal target output as 0; when made cut-in-hostlane action continuously output as 1; when target appeared from edge of FOV and target only partially visible output as 2. Not valid for cyclist and pedestrian";
CM_ SG_ 1075 ObstacleAngle "The heading angle of vehicle or cyclist, not valid pedestrian";
CM_ SG_ 1075 ObstacleAngleStd "The standard deviation of heading angle of obstacle, calculated from Tracking Filter";
CM_ SG_ 1075 ObstacleVelXAbs "The abusolute longitude velocity of the obstacle. ";
CM_ SG_ 1075 ObstacleVelYAbs "The abusolute lateral velocity of the obstacle. ";
CM_ SG_ 1075 RollingCounter_Obstacle4 "Rolling Counter of the msg ObstacleDataA4~ObstacleDataF4, Rolling between 0 and 15 SPI frame by SPI frame";
CM_ SG_ 1075 Checksum_Obstacle4 "CRC Checksum of the msg ObstacleDataA4~ObstacleDataF4, all the signals except Checksum_Obstacle_Signal are included. CRC4 algorithm.";
CM_ SG_ 1074 ObstaclePosXSTD "the standard deviation of longitudinal distance (ObstaclePosX) to observation point of obstacle in VCS, calculated from Tracking Filter";
CM_ SG_ 1074 ObstaclePosYSTD "the standard deviation of lateral distance (ObstaclePosY) to observation point of obstacle in VCS, calculated from Tracking Filter  ";
CM_ SG_ 1074 ObstacleVelXSTD "the standard deviation of longitude velocity (ObstacleVelX) of the obstacle, calculated from Tracking Filter  ";
CM_ SG_ 1074 ObstacleVelYSTD "the standard deviation of  lateral velocity (ObstacleVelY) of the obstacle, calculated from Tracking Filter  ";
CM_ SG_ 1074 ObstacleAccY "The lateral absolute acceleration of the object.";
CM_ SG_ 1073 ObstaclePosX "The longitudinal distance to observation point of obstacle in VCS";
CM_ SG_ 1073 ObstaclePosY "The lateral distance to observation point of obstacle in VCS, left positive, right negative";
CM_ SG_ 1073 ObstacleVelX "The relative longitude velocity of the obstacle and host vehicle";
CM_ SG_ 1073 ObstacleVelY "The relative lateral velocity of the obstacle and host vehicle, left positive, right negative";
CM_ SG_ 1073 ObstacleAccX "The longitude absolute acceleration of the object.";
CM_ SG_ 1072 ObstacleLength "Length of obstacle, valid for vehicle and cyclist. For pedestrian output as 0.";
CM_ SG_ 1072 ObstacleWidth "Width of obstacle rear, valid for vehicle and cyclist. For pedestrian output as 0.";
CM_ SG_ 1072 ObstacleHeight "Height of obstacle, valid for vehicle, cyclist and pedestrian";
CM_ SG_ 1072 CIPVFlag "If this obstacle CIPV, closest target(vehicle and cyclist) in path. Calculated by fusion of host lane path and predicted path";
CM_ SG_ 1072 MCPFlag "If this obstacle MCP, most critical target(pedestrian). Calculated by fusion of host lane path and predicted path";
CM_ SG_ 1072 ObstacleBlinkerInfo "Turn light signal in single frame, just valid for vehicle target. ";
CM_ SG_ 1072 ObstacleBrakeLights "Brake light signal in single frame, just valid for vehicle target";
CM_ SG_ 1072 ObstacleCenterAngle "The Angle Between the orientation of Host Vehicle and the orientation from the front center of Host Vehicle  to the Reference Point of the target. Mainly used when fusion with front Radar";
CM_ SG_ 1072 ObstaclePositionType "Observation point type of the obstacle, mainly depending on the heading angle of the obstacle. For preceding or oncoming target, output as 2; for crossing or turning target, output as 7 or 8. Just valid for vehicle target";
CM_ SG_ 1072 Obstacle_TTC "eTTC value for this obstacle, calculated from target perception distance, velocity and deceleration, by the method of enhanced TTC";
CM_ SG_ 1071 ObstacleID "Object ID, valid value is 1 to 255, 0 as default. 1 to 200 for vehicle, 201 to 255 for pedestrian";
CM_ SG_ 1071 ObstacleValid "Obstacle Valid info, when target exists, 'ObstacleValid'=1 in first frame, 'ObstacleValid'=2 from second frame";
CM_ SG_ 1071 ObstacleReplaced "Reserved";
CM_ SG_ 1071 ObstacleAge "Frame age of this obstacle exists, because some post-process logic to ensure the tracking status and confidence, in the first frame maybe not be '1'";
CM_ SG_ 1071 ObstacleConfidence "Existence probability of Obstacle, calculated from CNN detection, when > 6 continuously means high conf obstacle target. ";
CM_ SG_ 1071 ObstacleMotionCategory "The signal is based on our estimation of where the target is now relatively to the lanes, its rate of change, and our estimation of where it is going to be within one second. Just valid when 'ObstacleClass'=1, vehicle target";
CM_ SG_ 1071 ObstacleMotionStatus "The target is moving or stopped. Just valid when 'ObstacleClass'=1, vehicle target";
CM_ SG_ 1071 ObstacleMeasuringStatus "Were measurements predicted, old, or not valid, 'PREDICTED' will be continuously less than 3 frames";
CM_ SG_ 1071 ObstacleClass "Classification of this object";
CM_ SG_ 1071 VehicleSubType "Vehicle Sub type, when 'ObstacleClass'=1";
CM_ SG_ 1071 PedSubType "Pedestrian Sub type, when 'ObstacleClass'=2";
CM_ SG_ 1071 PedPos "Pedestrian posture, for normal standing person, output as 'Pedestrian'. For cyclist, no further posture could be classificated";
CM_ SG_ 1071 PedOrientation "Pedestrian orientation, classification in single frame in image space";
CM_ SG_ 1071 ObstacleLaneAssignment "Obstacle Lane Assignment £¨Which lane a vehicle belongs to£©";
CM_ SG_ 1071 ObstacleOccluded "Obstacle is occluded or not in image space. Just when the obstacle was partially occluded could output as 2";
CM_ SG_ 1066 ObjCornerPointPoxX "The longitudinal distance of the obstacle's nearest coner to host vehicle in VCS. Most situation the corner point is the potential cut-in frontal corner point. Not valid for cyclist and pedestrian";
CM_ SG_ 1066 CutInDistance "The lateral relative distance of the obstacle's nearest coner to host lane line center. Positive means the vehicle now out of host lane, negative means the vehicle had been part in host lane. Not valid for cyclist and pedestrian";
CM_ SG_ 1066 ObjCornerPointPoxY "The lateral distance of the obstacle's nearest coner to host vehicle in VCS. Most situation the corner point is the potential cut-in frontal corner point. Not valid for cyclist and pedestrian";
CM_ SG_ 1066 ObstacleCurvatureRadius "Curvature radius of obstacle, the tendency of turning, calculated by single frame, mainly used when fusion with Radar";
CM_ SG_ 1066 ObstacleTrackingConfidence "Obstacle Tracking Confidence, which judged the confidence of tracking status.";
CM_ SG_ 1066 CutInFlag "Cut-in status for obstacle. Normal target output as 0; when made cut-in-hostlane action continuously output as 1; when target appeared from edge of FOV and target only partially visible output as 2. Not valid for cyclist and pedestrian";
CM_ SG_ 1065 ObstacleAngle "The heading angle of vehicle or cyclist, not valid pedestrian";
CM_ SG_ 1065 ObstacleAngleStd "The standard deviation of heading angle of obstacle, calculated from Tracking Filter";
CM_ SG_ 1065 ObstacleVelXAbs "The abusolute longitude velocity of the obstacle. ";
CM_ SG_ 1065 ObstacleVelYAbs "The abusolute lateral velocity of the obstacle. ";
CM_ SG_ 1065 RollingCounter_Obstacle3 "Rolling Counter of the msg ObstacleDataA3~ObstacleDataF3, Rolling between 0 and 15 SPI frame by SPI frame";
CM_ SG_ 1065 Checksum_Obstacle3 "CRC Checksum of the msg ObstacleDataA3~ObstacleDataF3, all the signals except Checksum_Obstacle_Signal are included. CRC4 algorithm.";
CM_ SG_ 1064 ObstaclePosXSTD "the standard deviation of longitudinal distance (ObstaclePosX) to observation point of obstacle in VCS, calculated from Tracking Filter";
CM_ SG_ 1064 ObstaclePosYSTD "the standard deviation of lateral distance (ObstaclePosY) to observation point of obstacle in VCS, calculated from Tracking Filter  ";
CM_ SG_ 1064 ObstacleVelXSTD "the standard deviation of longitude velocity (ObstacleVelX) of the obstacle, calculated from Tracking Filter  ";
CM_ SG_ 1064 ObstacleVelYSTD "the standard deviation of  lateral velocity (ObstacleVelY) of the obstacle, calculated from Tracking Filter  ";
CM_ SG_ 1064 ObstacleAccY "The lateral absolute acceleration of the object.";
CM_ SG_ 1063 ObstaclePosX "The longitudinal distance to observation point of obstacle in VCS";
CM_ SG_ 1063 ObstaclePosY "The lateral distance to observation point of obstacle in VCS, left positive, right negative";
CM_ SG_ 1063 ObstacleVelX "The relative longitude velocity of the obstacle and host vehicle";
CM_ SG_ 1063 ObstacleVelY "The relative lateral velocity of the obstacle and host vehicle, left positive, right negative";
CM_ SG_ 1063 ObstacleAccX "The longitude absolute acceleration of the object.";
CM_ SG_ 1062 ObstacleLength "Length of obstacle, valid for vehicle and cyclist. For pedestrian output as 0.";
CM_ SG_ 1062 ObstacleWidth "Width of obstacle rear, valid for vehicle and cyclist. For pedestrian output as 0.";
CM_ SG_ 1062 ObstacleHeight "Height of obstacle, valid for vehicle, cyclist and pedestrian";
CM_ SG_ 1062 CIPVFlag "If this obstacle CIPV, closest target(vehicle and cyclist) in path. Calculated by fusion of host lane path and predicted path";
CM_ SG_ 1062 MCPFlag "If this obstacle MCP, most critical target(pedestrian). Calculated by fusion of host lane path and predicted path";
CM_ SG_ 1062 ObstacleBlinkerInfo "Turn light signal in single frame, just valid for vehicle target. ";
CM_ SG_ 1062 ObstacleBrakeLights "Brake light signal in single frame, just valid for vehicle target";
CM_ SG_ 1062 ObstacleCenterAngle "The Angle Between the orientation of Host Vehicle and the orientation from the front center of Host Vehicle  to the Reference Point of the target. Mainly used when fusion with front Radar";
CM_ SG_ 1062 ObstaclePositionType "Observation point type of the obstacle, mainly depending on the heading angle of the obstacle. For preceding or oncoming target, output as 2; for crossing or turning target, output as 7 or 8. Just valid for vehicle target";
CM_ SG_ 1062 Obstacle_TTC "eTTC value for this obstacle, calculated from target perception distance, velocity and deceleration, by the method of enhanced TTC";
CM_ SG_ 1061 ObstacleID "Object ID, valid value is 1 to 255, 0 as default. 1 to 200 for vehicle, 201 to 255 for pedestrian";
CM_ SG_ 1061 ObstacleValid "Obstacle Valid info, when target exists, 'ObstacleValid'=1 in first frame, 'ObstacleValid'=2 from second frame";
CM_ SG_ 1061 ObstacleReplaced "Reserved";
CM_ SG_ 1061 ObstacleAge "Frame age of this obstacle exists, because some post-process logic to ensure the tracking status and confidence, in the first frame maybe not be '1'";
CM_ SG_ 1061 ObstacleConfidence "Existence probability of Obstacle, calculated from CNN detection, when > 6 continuously means high conf obstacle target. ";
CM_ SG_ 1061 ObstacleMotionCategory "The signal is based on our estimation of where the target is now relatively to the lanes, its rate of change, and our estimation of where it is going to be within one second. Just valid when 'ObstacleClass'=1, vehicle target";
CM_ SG_ 1061 ObstacleMotionStatus "The target is moving or stopped. Just valid when 'ObstacleClass'=1, vehicle target";
CM_ SG_ 1061 ObstacleMeasuringStatus "Were measurements predicted, old, or not valid, 'PREDICTED' will be continuously less than 3 frames";
CM_ SG_ 1061 ObstacleClass "Classification of this object";
CM_ SG_ 1061 VehicleSubType "Vehicle Sub type, when 'ObstacleClass'=1";
CM_ SG_ 1061 PedSubType "Pedestrian Sub type, when 'ObstacleClass'=2";
CM_ SG_ 1061 PedPos "Pedestrian posture, for normal standing person, output as 'Pedestrian'. For cyclist, no further posture could be classificated";
CM_ SG_ 1061 PedOrientation "Pedestrian orientation, classification in single frame in image space";
CM_ SG_ 1061 ObstacleLaneAssignment "Obstacle Lane Assignment £¨Which lane a vehicle belongs to£©";
CM_ SG_ 1061 ObstacleOccluded "Obstacle is occluded or not in image space. Just when the obstacle was partially occluded could output as 2";
CM_ SG_ 1056 ObjCornerPointPoxX "The longitudinal distance of the obstacle's nearest coner to host vehicle in VCS. Most situation the corner point is the potential cut-in frontal corner point. Not valid for cyclist and pedestrian";
CM_ SG_ 1056 CutInDistance "The lateral relative distance of the obstacle's nearest coner to host lane line center. Positive means the vehicle now out of host lane, negative means the vehicle had been part in host lane. Not valid for cyclist and pedestrian";
CM_ SG_ 1056 ObjCornerPointPoxY "The lateral distance of the obstacle's nearest coner to host vehicle in VCS. Most situation the corner point is the potential cut-in frontal corner point. Not valid for cyclist and pedestrian";
CM_ SG_ 1056 ObstacleCurvatureRadius "Curvature radius of obstacle, the tendency of turning, calculated by single frame, mainly used when fusion with Radar";
CM_ SG_ 1056 ObstacleTrackingConfidence "Obstacle Tracking Confidence, which judged the confidence of tracking status.";
CM_ SG_ 1056 CutInFlag "Cut-in status for obstacle. Normal target output as 0; when made cut-in-hostlane action continuously output as 1; when target appeared from edge of FOV and target only partially visible output as 2. Not valid for cyclist and pedestrian";
CM_ SG_ 1055 ObstacleAngle "The heading angle of vehicle or cyclist, not valid pedestrian";
CM_ SG_ 1055 ObstacleAngleStd "The standard deviation of heading angle of obstacle, calculated from Tracking Filter";
CM_ SG_ 1055 ObstacleVelXAbs "The abusolute longitude velocity of the obstacle. ";
CM_ SG_ 1055 ObstacleVelYAbs "The abusolute lateral velocity of the obstacle. ";
CM_ SG_ 1055 RollingCounter_Obstacle2 "Rolling Counter of the msg ObstacleDataA2~ObstacleDataF2, Rolling between 0 and 15 SPI frame by SPI frame";
CM_ SG_ 1055 Checksum_Obstacle2 "CRC Checksum of the msg ObstacleDataA2~ObstacleDataF2, all the signals except Checksum_Obstacle_Signal are included. CRC4 algorithm.";
CM_ SG_ 1054 ObstaclePosXSTD "the standard deviation of longitudinal distance (ObstaclePosX) to observation point of obstacle in VCS, calculated from Tracking Filter";
CM_ SG_ 1054 ObstaclePosYSTD "the standard deviation of lateral distance (ObstaclePosY) to observation point of obstacle in VCS, calculated from Tracking Filter  ";
CM_ SG_ 1054 ObstacleVelXSTD "the standard deviation of longitude velocity (ObstacleVelX) of the obstacle, calculated from Tracking Filter  ";
CM_ SG_ 1054 ObstacleVelYSTD "the standard deviation of  lateral velocity (ObstacleVelY) of the obstacle, calculated from Tracking Filter  ";
CM_ SG_ 1054 ObstacleAccY "The lateral absolute acceleration of the object.";
CM_ SG_ 1053 ObstaclePosX "The longitudinal distance to observation point of obstacle in VCS";
CM_ SG_ 1053 ObstaclePosY "The lateral distance to observation point of obstacle in VCS, left positive, right negative";
CM_ SG_ 1053 ObstacleVelX "The relative longitude velocity of the obstacle and host vehicle";
CM_ SG_ 1053 ObstacleVelY "The relative lateral velocity of the obstacle and host vehicle, left positive, right negative";
CM_ SG_ 1053 ObstacleAccX "The longitude absolute acceleration of the object.";
CM_ SG_ 1052 ObstacleLength "Length of obstacle, valid for vehicle and cyclist. For pedestrian output as 0.";
CM_ SG_ 1052 ObstacleWidth "Width of obstacle rear, valid for vehicle and cyclist. For pedestrian output as 0.";
CM_ SG_ 1052 ObstacleHeight "Height of obstacle, valid for vehicle, cyclist and pedestrian";
CM_ SG_ 1052 CIPVFlag "If this obstacle CIPV, closest target(vehicle and cyclist) in path. Calculated by fusion of host lane path and predicted path";
CM_ SG_ 1052 MCPFlag "If this obstacle MCP, most critical target(pedestrian). Calculated by fusion of host lane path and predicted path";
CM_ SG_ 1052 ObstacleBlinkerInfo "Turn light signal in single frame, just valid for vehicle target. ";
CM_ SG_ 1052 ObstacleBrakeLights "Brake light signal in single frame, just valid for vehicle target";
CM_ SG_ 1052 ObstacleCenterAngle "The Angle Between the orientation of Host Vehicle and the orientation from the front center of Host Vehicle  to the Reference Point of the target. Mainly used when fusion with front Radar";
CM_ SG_ 1052 ObstaclePositionType "Observation point type of the obstacle, mainly depending on the heading angle of the obstacle. For preceding or oncoming target, output as 2; for crossing or turning target, output as 7 or 8. Just valid for vehicle target";
CM_ SG_ 1052 Obstacle_TTC "eTTC value for this obstacle, calculated from target perception distance, velocity and deceleration, by the method of enhanced TTC";
CM_ SG_ 1051 ObstacleID "Object ID, valid value is 1 to 255, 0 as default. 1 to 200 for vehicle, 201 to 255 for pedestrian";
CM_ SG_ 1051 ObstacleValid "Obstacle Valid info, when target exists, 'ObstacleValid'=1 in first frame, 'ObstacleValid'=2 from second frame";
CM_ SG_ 1051 ObstacleReplaced "Reserved";
CM_ SG_ 1051 ObstacleAge "Frame age of this obstacle exists, because some post-process logic to ensure the tracking status and confidence, in the first frame maybe not be '1'";
CM_ SG_ 1051 ObstacleConfidence "Existence probability of Obstacle, calculated from CNN detection, when > 6 continuously means high conf obstacle target. ";
CM_ SG_ 1051 ObstacleMotionCategory "The signal is based on our estimation of where the target is now relatively to the lanes, its rate of change, and our estimation of where it is going to be within one second. Just valid when 'ObstacleClass'=1, vehicle target";
CM_ SG_ 1051 ObstacleMotionStatus "The target is moving or stopped. Just valid when 'ObstacleClass'=1, vehicle target";
CM_ SG_ 1051 ObstacleMeasuringStatus "Were measurements predicted, old, or not valid, 'PREDICTED' will be continuously less than 3 frames";
CM_ SG_ 1051 ObstacleClass "Classification of this object";
CM_ SG_ 1051 VehicleSubType "Vehicle Sub type, when 'ObstacleClass'=1";
CM_ SG_ 1051 PedSubType "Pedestrian Sub type, when 'ObstacleClass'=2";
CM_ SG_ 1051 PedPos "Pedestrian posture, for normal standing person, output as 'Pedestrian'. For cyclist, no further posture could be classificated";
CM_ SG_ 1051 PedOrientation "Pedestrian orientation, classification in single frame in image space";
CM_ SG_ 1051 ObstacleLaneAssignment "Obstacle Lane Assignment £¨Which lane a vehicle belongs to£©";
CM_ SG_ 1051 ObstacleOccluded "Obstacle is occluded or not in image space. Just when the obstacle was partially occluded could output as 2";
CM_ SG_ 1046 ObjCornerPointPoxX "The longitudinal distance of the obstacle's nearest coner to host vehicle in VCS. Most situation the corner point is the potential cut-in frontal corner point. Not valid for cyclist and pedestrian";
CM_ SG_ 1046 CutInDistance "The lateral relative distance of the obstacle's nearest coner to host lane line center. Positive means the vehicle now out of host lane, negative means the vehicle had been part in host lane. Not valid for cyclist and pedestrian";
CM_ SG_ 1046 ObjCornerPointPoxY "The lateral distance of the obstacle's nearest coner to host vehicle in VCS. Most situation the corner point is the potential cut-in frontal corner point. Not valid for cyclist and pedestrian";
CM_ SG_ 1046 ObstacleCurvatureRadius "Curvature radius of obstacle, the tendency of turning, calculated by single frame, mainly used when fusion with Radar";
CM_ SG_ 1046 ObstacleTrackingConfidence "Obstacle Tracking Confidence, which judged the confidence of tracking status.";
CM_ SG_ 1046 CutInFlag "Cut-in status for obstacle. Normal target output as 0; when made cut-in-hostlane action continuously output as 1; when target appeared from edge of FOV and target only partially visible output as 2. Not valid for cyclist and pedestrian";
CM_ SG_ 1045 ObstacleAngle "The heading angle of vehicle or cyclist, not valid pedestrian";
CM_ SG_ 1045 ObstacleAngleStd "The standard deviation of heading angle of obstacle, calculated from Tracking Filter";
CM_ SG_ 1045 ObstacleVelXAbs "The abusolute longitude velocity of the obstacle. ";
CM_ SG_ 1045 ObstacleVelYAbs "The abusolute lateral velocity of the obstacle. ";
CM_ SG_ 1045 RollingCounter_Obstacle1 "Rolling Counter of the msg ObstacleDataA1~ObstacleDataF1, Rolling between 0 and 15 SPI frame by SPI frame";
CM_ SG_ 1045 Checksum_Obstacle1 "CRC Checksum of the msg ObstacleDataA1~ObstacleDataF1, all the signals except Checksum_Obstacle_Signal are included. CRC4 algorithm.";
CM_ SG_ 1044 ObstaclePosXSTD "the standard deviation of longitudinal distance (ObstaclePosX) to observation point of obstacle in VCS, calculated from Tracking Filter";
CM_ SG_ 1044 ObstaclePosYSTD "the standard deviation of lateral distance (ObstaclePosY) to observation point of obstacle in VCS, calculated from Tracking Filter  ";
CM_ SG_ 1044 ObstacleVelXSTD "the standard deviation of longitude velocity (ObstacleVelX) of the obstacle, calculated from Tracking Filter  ";
CM_ SG_ 1044 ObstacleVelYSTD "the standard deviation of  lateral velocity (ObstacleVelY) of the obstacle, calculated from Tracking Filter  ";
CM_ SG_ 1044 ObstacleAccY "The lateral absolute acceleration of the object.";
CM_ SG_ 1043 ObstaclePosX "The longitudinal distance to observation point of obstacle in VCS";
CM_ SG_ 1043 ObstaclePosY "The lateral distance to observation point of obstacle in VCS, left positive, right negative";
CM_ SG_ 1043 ObstacleVelX "The relative longitude velocity of the obstacle and host vehicle";
CM_ SG_ 1043 ObstacleVelY "The relative lateral velocity of the obstacle and host vehicle, left positive, right negative";
CM_ SG_ 1043 ObstacleAccX "The longitude absolute acceleration of the object.";
CM_ SG_ 1042 ObstacleLength "Length of obstacle, valid for vehicle and cyclist. For pedestrian output as 0.";
CM_ SG_ 1042 ObstacleWidth "Width of obstacle rear, valid for vehicle and cyclist. For pedestrian output as 0.";
CM_ SG_ 1042 ObstacleHeight "Height of obstacle, valid for vehicle, cyclist and pedestrian";
CM_ SG_ 1042 CIPVFlag "If this obstacle CIPV, closest target(vehicle and cyclist) in path. Calculated by fusion of host lane path and predicted path";
CM_ SG_ 1042 MCPFlag "If this obstacle MCP, most critical target(pedestrian). Calculated by fusion of host lane path and predicted path";
CM_ SG_ 1042 ObstacleBlinkerInfo "Turn light signal in single frame, just valid for vehicle target. ";
CM_ SG_ 1042 ObstacleBrakeLights "Brake light signal in single frame, just valid for vehicle target";
CM_ SG_ 1042 ObstacleCenterAngle "The Angle Between the orientation of Host Vehicle and the orientation from the front center of Host Vehicle  to the Reference Point of the target. Mainly used when fusion with front Radar";
CM_ SG_ 1042 ObstaclePositionType "Observation point type of the obstacle, mainly depending on the heading angle of the obstacle. For preceding or oncoming target, output as 2; for crossing or turning target, output as 7 or 8. Just valid for vehicle target";
CM_ SG_ 1042 Obstacle_TTC "eTTC value for this obstacle, calculated from target perception distance, velocity and deceleration, by the method of enhanced TTC";
CM_ SG_ 1041 ObstacleID "Object ID, valid value is 1 to 255, 0 as default. 1 to 200 for vehicle, 201 to 255 for pedestrian";
CM_ SG_ 1041 ObstacleValid "Obstacle Valid info, when target exists, 'ObstacleValid'=1 in first frame, 'ObstacleValid'=2 from second frame";
CM_ SG_ 1041 ObstacleReplaced "Reserved";
CM_ SG_ 1041 ObstacleAge "Frame age of this obstacle exists, because some post-process logic to ensure the tracking status and confidence, in the first frame maybe not be '1'";
CM_ SG_ 1041 ObstacleConfidence "Existence probability of Obstacle, calculated from CNN detection, when > 6 continuously means high conf obstacle target. ";
CM_ SG_ 1041 ObstacleMotionCategory "The signal is based on our estimation of where the target is now relatively to the lanes, its rate of change, and our estimation of where it is going to be within one second. Just valid when 'ObstacleClass'=1, vehicle target";
CM_ SG_ 1041 ObstacleMotionStatus "The target is moving or stopped. Just valid when 'ObstacleClass'=1, vehicle target";
CM_ SG_ 1041 ObstacleMeasuringStatus "Were measurements predicted, old, or not valid, 'PREDICTED' will be continuously less than 3 frames";
CM_ SG_ 1041 ObstacleClass "Classification of this object";
CM_ SG_ 1041 VehicleSubType "Vehicle Sub type, when 'ObstacleClass'=1";
CM_ SG_ 1041 PedSubType "Pedestrian Sub type, when 'ObstacleClass'=2";
CM_ SG_ 1041 PedPos "Pedestrian posture, for normal standing person, output as 'Pedestrian'. For cyclist, no further posture could be classificated";
CM_ SG_ 1041 PedOrientation "Pedestrian orientation, classification in single frame in image space";
CM_ SG_ 1041 ObstacleLaneAssignment "Obstacle Lane Assignment £¨Which lane a vehicle belongs to£©";
CM_ SG_ 1041 ObstacleOccluded "Obstacle is occluded or not in image space. Just when the obstacle was partially occluded could output as 2";
CM_ SG_ 1250 Obstacle_Internal_ID19 "Internal obstacle id of No.19 Obstacle, means the obstacle id of the same one from ETHERNET PROTO";
CM_ SG_ 1250 Obstacle_Internal_ID20 "Internal obstacle id of No.20 Obstacle, means the obstacle id of the same one from ETHERNET PROTO";
CM_ SG_ 1249 Obstacle_Internal_ID17 "Internal obstacle id of No.17 Obstacle, means the obstacle id of the same one from ETHERNET PROTO";
CM_ SG_ 1249 Obstacle_Internal_ID18 "Internal obstacle id of No.18 Obstacle, means the obstacle id of the same one from ETHERNET PROTO";
CM_ SG_ 1248 Obstacle_Internal_ID15 "Internal obstacle id of No.15 Obstacle, means the obstacle id of the same one from ETHERNET PROTO";
CM_ SG_ 1248 Obstacle_Internal_ID16 "Internal obstacle id of No.16 Obstacle, means the obstacle id of the same one from ETHERNET PROTO";
CM_ SG_ 1247 Obstacle_Internal_ID13 "Internal obstacle id of No.13 Obstacle, means the obstacle id of the same one from ETHERNET PROTO";
CM_ SG_ 1247 Obstacle_Internal_ID14 "Internal obstacle id of No.14 Obstacle, means the obstacle id of the same one from ETHERNET PROTO";
CM_ SG_ 1246 Obstacle_Internal_ID11 "Internal obstacle id of No.11 Obstacle, means the obstacle id of the same one from ETHERNET PROTO";
CM_ SG_ 1246 Obstacle_Internal_ID12 "Internal obstacle id of No.12 Obstacle, means the obstacle id of the same one from ETHERNET PROTO";
CM_ SG_ 1245 Obstacle_Internal_ID9 "Internal obstacle id of No.7 Obstacle, means the obstacle id of the same one from ETHERNET PROTO";
CM_ SG_ 1245 Obstacle_Internal_ID10 "Internal obstacle id of No.8 Obstacle, means the obstacle id of the same one from ETHERNET PROTO";
CM_ SG_ 1244 Obstacle_Internal_ID7 "Internal obstacle id of No.7 Obstacle, means the obstacle id of the same one from ETHERNET PROTO";
CM_ SG_ 1244 Obstacle_Internal_ID8 "Internal obstacle id of No.8 Obstacle, means the obstacle id of the same one from ETHERNET PROTO";
CM_ SG_ 1243 Obstacle_Internal_ID5 "Internal obstacle id of No.5 Obstacle, means the obstacle id of the same one from ETHERNET PROTO";
CM_ SG_ 1243 Obstacle_Internal_ID6 "Internal obstacle id of No.6 Obstacle, means the obstacle id of the same one from ETHERNET PROTO";
CM_ SG_ 1242 Obstacle_Internal_ID3 "Internal obstacle id of No.3 Obstacle, means the obstacle id of the same one from ETHERNET PROTO";
CM_ SG_ 1242 Obstacle_Internal_ID4 "Internal obstacle id of No.4 Obstacle, means the obstacle id of the same one from ETHERNET PROTO";
CM_ SG_ 1241 Obstacle_Internal_ID1 "Internal obstacle id of No.1 Obstacle, means the obstacle id of the same one from ETHERNET PROTO";
CM_ SG_ 1241 Obstacle_Internal_ID2 "Internal obstacle id of No.2 Obstacle, means the obstacle id of the same one from ETHERNET PROTO";
CM_ SG_ 1279 RollingCounter_Obstacle "Rolling Counter of the msg in the whole hb_Obstacle subfunction, Rolling between 0 and 15 SPI frame by SPI frame";
CM_ SG_ 1279 reserved_0 "reserved bit";
CM_ SG_ 1279 CRCChecksum_Obstacle "CRC Checksum of the msg in the whole hb_Obstacle subfunction, all the signals except CRCChecksum_Obstacle are included. CRC16 algorithm.";
VAL_ 1131 ObstacleValid 2 "older valid" 1 "new valid (detected this frame)" 0 "invalid Obstacle(default value)" ;
VAL_ 1131 ObstacleReplaced 1 "replaced in this frame" 0 "not replaced in this frame" ;
VAL_ 1131 ObstacleMotionCategory 13 "ONCOMING" 12 "PRECEEDING" 11 "MOVING" 10 "RTAP" 9 "LTAP" 8 "CROSSING" 7 "MOVING_OUT" 6 "MOVING_IN" 5 "CLOSE_CUT_IN" 4 "PASSING_OUT" 3 "PASSING_IN" 2 "PASSING" 1 "UNDEFINED" 0 "INVALID" ;
VAL_ 1131 ObstacleMotionStatus 5 "MOVING SLOWLY" 4 "STOPPED" 3 "STATIONARY" 2 "MOVING" 1 "UNKNOWN" 0 "INVALID" ;
VAL_ 1131 ObstacleMeasuringStatus 2 "PREDICTED" 1 "MEASURED" 0 "INVALID" ;
VAL_ 1131 ObstacleClass 4 "GENERAL_OBJECT(reserved)" 3 "CYCLIST" 2 "PEDESTRIAN" 1 "VEHICLE" 0 "INVALID" ;
VAL_ 1131 VehicleSubType 7 "Lorry" 6 "Tiny_car" 5 "Special_vehicle" 4 "Motors(Tri-cycle)" 3 "Trucks" 2 "Small_Medium_Car" 1 "Bus" 0 "Unknown" ;
VAL_ 1131 PedSubType 2 "Child" 1 "Adult" 0 "Unknown" ;
VAL_ 1131 PedPos 5 "Sitter" 4 "Pedestrian" 3 "Lier" 2 "Cyclist" 1 "Bended" 0 "Unknown" ;
VAL_ 1131 PedOrientation 8 "right_back" 7 "right_front" 6 "right" 5 "left_back" 4 "left_front" 3 "left" 2 "front" 1 "back" 0 "Unknown" ;
VAL_ 1131 ObstacleLaneAssignment 5 "RIGHT_RIGHT" 4 "RIGHT " 3 "HOST" 2 "LEFT" 1 "LEFT_LEFT" 0 "UNKNOWN" ;
VAL_ 1131 ObstacleOccluded 2 "Obstacle occluded" 1 "Obstacle not occluded" 0 "Default" ;
VAL_ 1126 CutInFlag 2 "close cut in" 1 "cut in" 0 "not cut in" ;
VAL_ 1122 CIPVFlag 1 "CIPV" 0 "not CIPV" ;
VAL_ 1122 MCPFlag 1 "MCP" 0 "not MCP" ;
VAL_ 1122 ObstacleBlinkerInfo 4 "Both" 3 "Right" 2 "Left" 1 "Off" 0 "Unavailable" ;
VAL_ 1122 ObstacleBrakeLights 1 "ON" 0 "OFF" ;
VAL_ 1122 ObstaclePositionType 9 "Center" 8 "RightCenter" 7 "LeftCenter" 6 "FrontRight" 5 "FrontCenter" 4 "FrontLeft" 3 "RearRight" 2 "RearCenter" 1 "RearLeft   " 0 "Unknown    " ;
VAL_ 1121 ObstacleValid 2 "older valid" 1 "new valid (detected this frame)" 0 "invalid Obstacle(default value)" ;
VAL_ 1121 ObstacleReplaced 1 "replaced in this frame" 0 "not replaced in this frame" ;
VAL_ 1121 ObstacleMotionCategory 13 "ONCOMING" 12 "PRECEEDING" 11 "MOVING" 10 "RTAP" 9 "LTAP" 8 "CROSSING" 7 "MOVING_OUT" 6 "MOVING_IN" 5 "CLOSE_CUT_IN" 4 "PASSING_OUT" 3 "PASSING_IN" 2 "PASSING" 1 "UNDEFINED" 0 "INVALID" ;
VAL_ 1121 ObstacleMotionStatus 5 "MOVING SLOWLY" 4 "STOPPED" 3 "STATIONARY" 2 "MOVING" 1 "UNKNOWN" 0 "INVALID" ;
VAL_ 1121 ObstacleMeasuringStatus 2 "PREDICTED" 1 "MEASURED" 0 "INVALID" ;
VAL_ 1121 ObstacleClass 4 "GENERAL_OBJECT(reserved)" 3 "CYCLIST" 2 "PEDESTRIAN" 1 "VEHICLE" 0 "INVALID" ;
VAL_ 1121 VehicleSubType 7 "Lorry" 6 "Tiny_car" 5 "Special_vehicle" 4 "Motors(Tri-cycle)" 3 "Trucks" 2 "Small_Medium_Car" 1 "Bus" 0 "Unknown" ;
VAL_ 1121 PedSubType 2 "Child" 1 "Adult" 0 "Unknown" ;
VAL_ 1121 PedPos 5 "Sitter" 4 "Pedestrian" 3 "Lier" 2 "Cyclist" 1 "Bended" 0 "Unknown" ;
VAL_ 1121 PedOrientation 8 "right_back" 7 "right_front" 6 "right" 5 "left_back" 4 "left_front" 3 "left" 2 "front" 1 "back" 0 "Unknown" ;
VAL_ 1121 ObstacleLaneAssignment 5 "RIGHT_RIGHT" 4 "RIGHT " 3 "HOST" 2 "LEFT" 1 "LEFT_LEFT" 0 "UNKNOWN" ;
VAL_ 1121 ObstacleOccluded 2 "Obstacle occluded" 1 "Obstacle not occluded" 0 "Default" ;
VAL_ 1116 CutInFlag 2 "close cut in" 1 "cut in" 0 "not cut in" ;
VAL_ 1112 CIPVFlag 1 "CIPV" 0 "not CIPV" ;
VAL_ 1112 MCPFlag 1 "MCP" 0 "not MCP" ;
VAL_ 1112 ObstacleBlinkerInfo 4 "Both" 3 "Right" 2 "Left" 1 "Off" 0 "Unavailable" ;
VAL_ 1112 ObstacleBrakeLights 1 "ON" 0 "OFF" ;
VAL_ 1112 ObstaclePositionType 9 "Center" 8 "RightCenter" 7 "LeftCenter" 6 "FrontRight" 5 "FrontCenter" 4 "FrontLeft" 3 "RearRight" 2 "RearCenter" 1 "RearLeft   " 0 "Unknown    " ;
VAL_ 1111 ObstacleValid 2 "older valid" 1 "new valid (detected this frame)" 0 "invalid Obstacle(default value)" ;
VAL_ 1111 ObstacleReplaced 1 "replaced in this frame" 0 "not replaced in this frame" ;
VAL_ 1111 ObstacleMotionCategory 13 "ONCOMING" 12 "PRECEEDING" 11 "MOVING" 10 "RTAP" 9 "LTAP" 8 "CROSSING" 7 "MOVING_OUT" 6 "MOVING_IN" 5 "CLOSE_CUT_IN" 4 "PASSING_OUT" 3 "PASSING_IN" 2 "PASSING" 1 "UNDEFINED" 0 "INVALID" ;
VAL_ 1111 ObstacleMotionStatus 5 "MOVING SLOWLY" 4 "STOPPED" 3 "STATIONARY" 2 "MOVING" 1 "UNKNOWN" 0 "INVALID" ;
VAL_ 1111 ObstacleMeasuringStatus 2 "PREDICTED" 1 "MEASURED" 0 "INVALID" ;
VAL_ 1111 ObstacleClass 4 "GENERAL_OBJECT(reserved)" 3 "CYCLIST" 2 "PEDESTRIAN" 1 "VEHICLE" 0 "INVALID" ;
VAL_ 1111 VehicleSubType 7 "Lorry" 6 "Tiny_car" 5 "Special_vehicle" 4 "Motors(Tri-cycle)" 3 "Trucks" 2 "Small_Medium_Car" 1 "Bus" 0 "Unknown" ;
VAL_ 1111 PedSubType 2 "Child" 1 "Adult" 0 "Unknown" ;
VAL_ 1111 PedPos 5 "Sitter" 4 "Pedestrian" 3 "Lier" 2 "Cyclist" 1 "Bended" 0 "Unknown" ;
VAL_ 1111 PedOrientation 8 "right_back" 7 "right_front" 6 "right" 5 "left_back" 4 "left_front" 3 "left" 2 "front" 1 "back" 0 "Unknown" ;
VAL_ 1111 ObstacleLaneAssignment 5 "RIGHT_RIGHT" 4 "RIGHT " 3 "HOST" 2 "LEFT" 1 "LEFT_LEFT" 0 "UNKNOWN" ;
VAL_ 1111 ObstacleOccluded 2 "Obstacle occluded" 1 "Obstacle not occluded" 0 "Default" ;
VAL_ 1106 CutInFlag 2 "close cut in" 1 "cut in" 0 "not cut in" ;
VAL_ 1102 CIPVFlag 1 "CIPV" 0 "not CIPV" ;
VAL_ 1102 MCPFlag 1 "MCP" 0 "not MCP" ;
VAL_ 1102 ObstacleBlinkerInfo 4 "Both" 3 "Right" 2 "Left" 1 "Off" 0 "Unavailable" ;
VAL_ 1102 ObstacleBrakeLights 1 "ON" 0 "OFF" ;
VAL_ 1102 ObstaclePositionType 9 "Center" 8 "RightCenter" 7 "LeftCenter" 6 "FrontRight" 5 "FrontCenter" 4 "FrontLeft" 3 "RearRight" 2 "RearCenter" 1 "RearLeft   " 0 "Unknown    " ;
VAL_ 1101 ObstacleValid 2 "older valid" 1 "new valid (detected this frame)" 0 "invalid Obstacle(default value)" ;
VAL_ 1101 ObstacleReplaced 1 "replaced in this frame" 0 "not replaced in this frame" ;
VAL_ 1101 ObstacleMotionCategory 13 "ONCOMING" 12 "PRECEEDING" 11 "MOVING" 10 "RTAP" 9 "LTAP" 8 "CROSSING" 7 "MOVING_OUT" 6 "MOVING_IN" 5 "CLOSE_CUT_IN" 4 "PASSING_OUT" 3 "PASSING_IN" 2 "PASSING" 1 "UNDEFINED" 0 "INVALID" ;
VAL_ 1101 ObstacleMotionStatus 5 "MOVING SLOWLY" 4 "STOPPED" 3 "STATIONARY" 2 "MOVING" 1 "UNKNOWN" 0 "INVALID" ;
VAL_ 1101 ObstacleMeasuringStatus 2 "PREDICTED" 1 "MEASURED" 0 "INVALID" ;
VAL_ 1101 ObstacleClass 4 "GENERAL_OBJECT(reserved)" 3 "CYCLIST" 2 "PEDESTRIAN" 1 "VEHICLE" 0 "INVALID" ;
VAL_ 1101 VehicleSubType 7 "Lorry" 6 "Tiny_car" 5 "Special_vehicle" 4 "Motors(Tri-cycle)" 3 "Trucks" 2 "Small_Medium_Car" 1 "Bus" 0 "Unknown" ;
VAL_ 1101 PedSubType 2 "Child" 1 "Adult" 0 "Unknown" ;
VAL_ 1101 PedPos 5 "Sitter" 4 "Pedestrian" 3 "Lier" 2 "Cyclist" 1 "Bended" 0 "Unknown" ;
VAL_ 1101 PedOrientation 8 "right_back" 7 "right_front" 6 "right" 5 "left_back" 4 "left_front" 3 "left" 2 "front" 1 "back" 0 "Unknown" ;
VAL_ 1101 ObstacleLaneAssignment 5 "RIGHT_RIGHT" 4 "RIGHT " 3 "HOST" 2 "LEFT" 1 "LEFT_LEFT" 0 "UNKNOWN" ;
VAL_ 1101 ObstacleOccluded 2 "Obstacle occluded" 1 "Obstacle not occluded" 0 "Default" ;
VAL_ 1096 CutInFlag 2 "close cut in" 1 "cut in" 0 "not cut in" ;
VAL_ 1092 CIPVFlag 1 "CIPV" 0 "not CIPV" ;
VAL_ 1092 MCPFlag 1 "MCP" 0 "not MCP" ;
VAL_ 1092 ObstacleBlinkerInfo 4 "Both" 3 "Right" 2 "Left" 1 "Off" 0 "Unavailable" ;
VAL_ 1092 ObstacleBrakeLights 1 "ON" 0 "OFF" ;
VAL_ 1092 ObstaclePositionType 9 "Center" 8 "RightCenter" 7 "LeftCenter" 6 "FrontRight" 5 "FrontCenter" 4 "FrontLeft" 3 "RearRight" 2 "RearCenter" 1 "RearLeft   " 0 "Unknown    " ;
VAL_ 1091 ObstacleValid 2 "older valid" 1 "new valid (detected this frame)" 0 "invalid Obstacle(default value)" ;
VAL_ 1091 ObstacleReplaced 1 "replaced in this frame" 0 "not replaced in this frame" ;
VAL_ 1091 ObstacleMotionCategory 13 "ONCOMING" 12 "PRECEEDING" 11 "MOVING" 10 "RTAP" 9 "LTAP" 8 "CROSSING" 7 "MOVING_OUT" 6 "MOVING_IN" 5 "CLOSE_CUT_IN" 4 "PASSING_OUT" 3 "PASSING_IN" 2 "PASSING" 1 "UNDEFINED" 0 "INVALID" ;
VAL_ 1091 ObstacleMotionStatus 5 "MOVING SLOWLY" 4 "STOPPED" 3 "STATIONARY" 2 "MOVING" 1 "UNKNOWN" 0 "INVALID" ;
VAL_ 1091 ObstacleMeasuringStatus 2 "PREDICTED" 1 "MEASURED" 0 "INVALID" ;
VAL_ 1091 ObstacleClass 4 "GENERAL_OBJECT(reserved)" 3 "CYCLIST" 2 "PEDESTRIAN" 1 "VEHICLE" 0 "INVALID" ;
VAL_ 1091 VehicleSubType 7 "Lorry" 6 "Tiny_car" 5 "Special_vehicle" 4 "Motors(Tri-cycle)" 3 "Trucks" 2 "Small_Medium_Car" 1 "Bus" 0 "Unknown" ;
VAL_ 1091 PedSubType 2 "Child" 1 "Adult" 0 "Unknown" ;
VAL_ 1091 PedPos 5 "Sitter" 4 "Pedestrian" 3 "Lier" 2 "Cyclist" 1 "Bended" 0 "Unknown" ;
VAL_ 1091 PedOrientation 8 "right_back" 7 "right_front" 6 "right" 5 "left_back" 4 "left_front" 3 "left" 2 "front" 1 "back" 0 "Unknown" ;
VAL_ 1091 ObstacleLaneAssignment 5 "RIGHT_RIGHT" 4 "RIGHT " 3 "HOST" 2 "LEFT" 1 "LEFT_LEFT" 0 "UNKNOWN" ;
VAL_ 1091 ObstacleOccluded 2 "Obstacle occluded" 1 "Obstacle not occluded" 0 "Default" ;
VAL_ 1086 CutInFlag 2 "close cut in" 1 "cut in" 0 "not cut in" ;
VAL_ 1082 CIPVFlag 1 "CIPV" 0 "not CIPV" ;
VAL_ 1082 MCPFlag 1 "MCP" 0 "not MCP" ;
VAL_ 1082 ObstacleBlinkerInfo 4 "Both" 3 "Right" 2 "Left" 1 "Off" 0 "Unavailable" ;
VAL_ 1082 ObstacleBrakeLights 1 "ON" 0 "OFF" ;
VAL_ 1082 ObstaclePositionType 9 "Center" 8 "RightCenter" 7 "LeftCenter" 6 "FrontRight" 5 "FrontCenter" 4 "FrontLeft" 3 "RearRight" 2 "RearCenter" 1 "RearLeft   " 0 "Unknown    " ;
VAL_ 1081 ObstacleValid 2 "older valid" 1 "new valid (detected this frame)" 0 "invalid Obstacle(default value)" ;
VAL_ 1081 ObstacleReplaced 1 "replaced in this frame" 0 "not replaced in this frame" ;
VAL_ 1081 ObstacleMotionCategory 13 "ONCOMING" 12 "PRECEEDING" 11 "MOVING" 10 "RTAP" 9 "LTAP" 8 "CROSSING" 7 "MOVING_OUT" 6 "MOVING_IN" 5 "CLOSE_CUT_IN" 4 "PASSING_OUT" 3 "PASSING_IN" 2 "PASSING" 1 "UNDEFINED" 0 "INVALID" ;
VAL_ 1081 ObstacleMotionStatus 5 "MOVING SLOWLY" 4 "STOPPED" 3 "STATIONARY" 2 "MOVING" 1 "UNKNOWN" 0 "INVALID" ;
VAL_ 1081 ObstacleMeasuringStatus 2 "PREDICTED" 1 "MEASURED" 0 "INVALID" ;
VAL_ 1081 ObstacleClass 4 "GENERAL_OBJECT(reserved)" 3 "CYCLIST" 2 "PEDESTRIAN" 1 "VEHICLE" 0 "INVALID" ;
VAL_ 1081 VehicleSubType 7 "Lorry" 6 "Tiny_car" 5 "Special_vehicle" 4 "Motors(Tri-cycle)" 3 "Trucks" 2 "Small_Medium_Car" 1 "Bus" 0 "Unknown" ;
VAL_ 1081 PedSubType 2 "Child" 1 "Adult" 0 "Unknown" ;
VAL_ 1081 PedPos 5 "Sitter" 4 "Pedestrian" 3 "Lier" 2 "Cyclist" 1 "Bended" 0 "Unknown" ;
VAL_ 1081 PedOrientation 8 "right_back" 7 "right_front" 6 "right" 5 "left_back" 4 "left_front" 3 "left" 2 "front" 1 "back" 0 "Unknown" ;
VAL_ 1081 ObstacleLaneAssignment 5 "RIGHT_RIGHT" 4 "RIGHT " 3 "HOST" 2 "LEFT" 1 "LEFT_LEFT" 0 "UNKNOWN" ;
VAL_ 1081 ObstacleOccluded 2 "Obstacle occluded" 1 "Obstacle not occluded" 0 "Default" ;
VAL_ 1076 CutInFlag 2 "close cut in" 1 "cut in" 0 "not cut in" ;
VAL_ 1072 CIPVFlag 1 "CIPV" 0 "not CIPV" ;
VAL_ 1072 MCPFlag 1 "MCP" 0 "not MCP" ;
VAL_ 1072 ObstacleBlinkerInfo 4 "Both" 3 "Right" 2 "Left" 1 "Off" 0 "Unavailable" ;
VAL_ 1072 ObstacleBrakeLights 1 "ON" 0 "OFF" ;
VAL_ 1072 ObstaclePositionType 9 "Center" 8 "RightCenter" 7 "LeftCenter" 6 "FrontRight" 5 "FrontCenter" 4 "FrontLeft" 3 "RearRight" 2 "RearCenter" 1 "RearLeft   " 0 "Unknown    " ;
VAL_ 1071 ObstacleValid 2 "older valid" 1 "new valid (detected this frame)" 0 "invalid Obstacle(default value)" ;
VAL_ 1071 ObstacleReplaced 1 "replaced in this frame" 0 "not replaced in this frame" ;
VAL_ 1071 ObstacleMotionCategory 13 "ONCOMING" 12 "PRECEEDING" 11 "MOVING" 10 "RTAP" 9 "LTAP" 8 "CROSSING" 7 "MOVING_OUT" 6 "MOVING_IN" 5 "CLOSE_CUT_IN" 4 "PASSING_OUT" 3 "PASSING_IN" 2 "PASSING" 1 "UNDEFINED" 0 "INVALID" ;
VAL_ 1071 ObstacleMotionStatus 5 "MOVING SLOWLY" 4 "STOPPED" 3 "STATIONARY" 2 "MOVING" 1 "UNKNOWN" 0 "INVALID" ;
VAL_ 1071 ObstacleMeasuringStatus 2 "PREDICTED" 1 "MEASURED" 0 "INVALID" ;
VAL_ 1071 ObstacleClass 4 "GENERAL_OBJECT(reserved)" 3 "CYCLIST" 2 "PEDESTRIAN" 1 "VEHICLE" 0 "INVALID" ;
VAL_ 1071 VehicleSubType 7 "Lorry" 6 "Tiny_car" 5 "Special_vehicle" 4 "Motors(Tri-cycle)" 3 "Trucks" 2 "Small_Medium_Car" 1 "Bus" 0 "Unknown" ;
VAL_ 1071 PedSubType 2 "Child" 1 "Adult" 0 "Unknown" ;
VAL_ 1071 PedPos 5 "Sitter" 4 "Pedestrian" 3 "Lier" 2 "Cyclist" 1 "Bended" 0 "Unknown" ;
VAL_ 1071 PedOrientation 8 "right_back" 7 "right_front" 6 "right" 5 "left_back" 4 "left_front" 3 "left" 2 "front" 1 "back" 0 "Unknown" ;
VAL_ 1071 ObstacleLaneAssignment 5 "RIGHT_RIGHT" 4 "RIGHT " 3 "HOST" 2 "LEFT" 1 "LEFT_LEFT" 0 "UNKNOWN" ;
VAL_ 1071 ObstacleOccluded 2 "Obstacle occluded" 1 "Obstacle not occluded" 0 "Default" ;
VAL_ 1066 CutInFlag 2 "close cut in" 1 "cut in" 0 "not cut in" ;
VAL_ 1062 CIPVFlag 1 "CIPV" 0 "not CIPV" ;
VAL_ 1062 MCPFlag 1 "MCP" 0 "not MCP" ;
VAL_ 1062 ObstacleBlinkerInfo 4 "Both" 3 "Right" 2 "Left" 1 "Off" 0 "Unavailable" ;
VAL_ 1062 ObstacleBrakeLights 1 "ON" 0 "OFF" ;
VAL_ 1062 ObstaclePositionType 9 "Center" 8 "RightCenter" 7 "LeftCenter" 6 "FrontRight" 5 "FrontCenter" 4 "FrontLeft" 3 "RearRight" 2 "RearCenter" 1 "RearLeft   " 0 "Unknown    " ;
VAL_ 1061 ObstacleValid 2 "older valid" 1 "new valid (detected this frame)" 0 "invalid Obstacle(default value)" ;
VAL_ 1061 ObstacleReplaced 1 "replaced in this frame" 0 "not replaced in this frame" ;
VAL_ 1061 ObstacleMotionCategory 13 "ONCOMING" 12 "PRECEEDING" 11 "MOVING" 10 "RTAP" 9 "LTAP" 8 "CROSSING" 7 "MOVING_OUT" 6 "MOVING_IN" 5 "CLOSE_CUT_IN" 4 "PASSING_OUT" 3 "PASSING_IN" 2 "PASSING" 1 "UNDEFINED" 0 "INVALID" ;
VAL_ 1061 ObstacleMotionStatus 5 "MOVING SLOWLY" 4 "STOPPED" 3 "STATIONARY" 2 "MOVING" 1 "UNKNOWN" 0 "INVALID" ;
VAL_ 1061 ObstacleMeasuringStatus 2 "PREDICTED" 1 "MEASURED" 0 "INVALID" ;
VAL_ 1061 ObstacleClass 4 "GENERAL_OBJECT(reserved)" 3 "CYCLIST" 2 "PEDESTRIAN" 1 "VEHICLE" 0 "INVALID" ;
VAL_ 1061 VehicleSubType 7 "Lorry" 6 "Tiny_car" 5 "Special_vehicle" 4 "Motors(Tri-cycle)" 3 "Trucks" 2 "Small_Medium_Car" 1 "Bus" 0 "Unknown" ;
VAL_ 1061 PedSubType 2 "Child" 1 "Adult" 0 "Unknown" ;
VAL_ 1061 PedPos 5 "Sitter" 4 "Pedestrian" 3 "Lier" 2 "Cyclist" 1 "Bended" 0 "Unknown" ;
VAL_ 1061 PedOrientation 8 "right_back" 7 "right_front" 6 "right" 5 "left_back" 4 "left_front" 3 "left" 2 "front" 1 "back" 0 "Unknown" ;
VAL_ 1061 ObstacleLaneAssignment 5 "RIGHT_RIGHT" 4 "RIGHT " 3 "HOST" 2 "LEFT" 1 "LEFT_LEFT" 0 "UNKNOWN" ;
VAL_ 1061 ObstacleOccluded 2 "Obstacle occluded" 1 "Obstacle not occluded" 0 "Default" ;
VAL_ 1056 CutInFlag 2 "close cut in" 1 "cut in" 0 "not cut in" ;
VAL_ 1052 CIPVFlag 1 "CIPV" 0 "not CIPV" ;
VAL_ 1052 MCPFlag 1 "MCP" 0 "not MCP" ;
VAL_ 1052 ObstacleBlinkerInfo 4 "Both" 3 "Right" 2 "Left" 1 "Off" 0 "Unavailable" ;
VAL_ 1052 ObstacleBrakeLights 1 "ON" 0 "OFF" ;
VAL_ 1052 ObstaclePositionType 9 "Center" 8 "RightCenter" 7 "LeftCenter" 6 "FrontRight" 5 "FrontCenter" 4 "FrontLeft" 3 "RearRight" 2 "RearCenter" 1 "RearLeft   " 0 "Unknown    " ;
VAL_ 1051 ObstacleValid 2 "older valid" 1 "new valid (detected this frame)" 0 "invalid Obstacle(default value)" ;
VAL_ 1051 ObstacleReplaced 1 "replaced in this frame" 0 "not replaced in this frame" ;
VAL_ 1051 ObstacleMotionCategory 13 "ONCOMING" 12 "PRECEEDING" 11 "MOVING" 10 "RTAP" 9 "LTAP" 8 "CROSSING" 7 "MOVING_OUT" 6 "MOVING_IN" 5 "CLOSE_CUT_IN" 4 "PASSING_OUT" 3 "PASSING_IN" 2 "PASSING" 1 "UNDEFINED" 0 "INVALID" ;
VAL_ 1051 ObstacleMotionStatus 5 "MOVING SLOWLY" 4 "STOPPED" 3 "STATIONARY" 2 "MOVING" 1 "UNKNOWN" 0 "INVALID" ;
VAL_ 1051 ObstacleMeasuringStatus 2 "PREDICTED" 1 "MEASURED" 0 "INVALID" ;
VAL_ 1051 ObstacleClass 4 "GENERAL_OBJECT(reserved)" 3 "CYCLIST" 2 "PEDESTRIAN" 1 "VEHICLE" 0 "INVALID" ;
VAL_ 1051 VehicleSubType 7 "Lorry" 6 "Tiny_car" 5 "Special_vehicle" 4 "Motors(Tri-cycle)" 3 "Trucks" 2 "Small_Medium_Car" 1 "Bus" 0 "Unknown" ;
VAL_ 1051 PedSubType 2 "Child" 1 "Adult" 0 "Unknown" ;
VAL_ 1051 PedPos 5 "Sitter" 4 "Pedestrian" 3 "Lier" 2 "Cyclist" 1 "Bended" 0 "Unknown" ;
VAL_ 1051 PedOrientation 8 "right_back" 7 "right_front" 6 "right" 5 "left_back" 4 "left_front" 3 "left" 2 "front" 1 "back" 0 "Unknown" ;
VAL_ 1051 ObstacleLaneAssignment 5 "RIGHT_RIGHT" 4 "RIGHT " 3 "HOST" 2 "LEFT" 1 "LEFT_LEFT" 0 "UNKNOWN" ;
VAL_ 1051 ObstacleOccluded 2 "Obstacle occluded" 1 "Obstacle not occluded" 0 "Default" ;
VAL_ 1046 CutInFlag 2 "close cut in" 1 "cut in" 0 "not cut in" ;
VAL_ 1042 CIPVFlag 1 "CIPV" 0 "not CIPV" ;
VAL_ 1042 MCPFlag 1 "MCP" 0 "not MCP" ;
VAL_ 1042 ObstacleBlinkerInfo 4 "Both" 3 "Right" 2 "Left" 1 "Off" 0 "Unavailable" ;
VAL_ 1042 ObstacleBrakeLights 1 "ON" 0 "OFF" ;
VAL_ 1042 ObstaclePositionType 9 "Center" 8 "RightCenter" 7 "LeftCenter" 6 "FrontRight" 5 "FrontCenter" 4 "FrontLeft" 3 "RearRight" 2 "RearCenter" 1 "RearLeft   " 0 "Unknown    " ;
VAL_ 1041 ObstacleValid 2 "older valid" 1 "new valid (detected this frame)" 0 "invalid Obstacle(default value)" ;
VAL_ 1041 ObstacleReplaced 1 "replaced in this frame" 0 "not replaced in this frame" ;
VAL_ 1041 ObstacleMotionCategory 13 "ONCOMING" 12 "PRECEEDING" 11 "MOVING" 10 "RTAP" 9 "LTAP" 8 "CROSSING" 7 "MOVING_OUT" 6 "MOVING_IN" 5 "CLOSE_CUT_IN" 4 "PASSING_OUT" 3 "PASSING_IN" 2 "PASSING" 1 "UNDEFINED" 0 "INVALID" ;
VAL_ 1041 ObstacleMotionStatus 5 "MOVING SLOWLY" 4 "STOPPED" 3 "STATIONARY" 2 "MOVING" 1 "UNKNOWN" 0 "INVALID" ;
VAL_ 1041 ObstacleMeasuringStatus 2 "PREDICTED" 1 "MEASURED" 0 "INVALID" ;
VAL_ 1041 ObstacleClass 4 "GENERAL_OBJECT(reserved)" 3 "CYCLIST" 2 "PEDESTRIAN" 1 "VEHICLE" 0 "INVALID" ;
VAL_ 1041 VehicleSubType 7 "Lorry" 6 "Tiny_car" 5 "Special_vehicle" 4 "Motors(Tri-cycle)" 3 "Trucks" 2 "Small_Medium_Car" 1 "Bus" 0 "Unknown" ;
VAL_ 1041 PedSubType 2 "Child" 1 "Adult" 0 "Unknown" ;
VAL_ 1041 PedPos 5 "Sitter" 4 "Pedestrian" 3 "Lier" 2 "Cyclist" 1 "Bended" 0 "Unknown" ;
VAL_ 1041 PedOrientation 8 "right_back" 7 "right_front" 6 "right" 5 "left_back" 4 "left_front" 3 "left" 2 "front" 1 "back" 0 "Unknown" ;
VAL_ 1041 ObstacleLaneAssignment 5 "RIGHT_RIGHT" 4 "RIGHT " 3 "HOST" 2 "LEFT" 1 "LEFT_LEFT" 0 "UNKNOWN" ;
VAL_ 1041 ObstacleOccluded 2 "Obstacle occluded" 1 "Obstacle not occluded" 0 "Default" ;
